VERSION "STEPFOC V108"

NS_ :

BS_:

BU_: Host Driver0 Driver1 Driver2 Driver3 Driver4 Driver5 Driver6 Driver7 Driver8 Driver9 Driver10 Driver11 Driver12 Driver13

BO_ 958 Send_data_pack_HALL_N7: 4 Host
 SG_ Speed : 7|24@0- (1,0) [-8388608|8388607] "" Driver7
 SG_ Trigger : 31|8@0+ (1,0) [0|255] "" Driver7

BO_ 902 Respond_data_pack_1_N7: 8 Driver7
 SG_ position : 7|24@0- (1,0) [-8388608|8388607] "" Host
 SG_ speed : 31|24@0- (1,0) [-8388608|8388607] "" Host
 SG_ current : 55|16@0- (1,0) [-32768|32767] "" Host

BO_ 903 Respond_data_pack_1_N7_Fault: 8 Driver7
 SG_ position : 7|24@0- (1,0) [-8388608|8388607] "" Host
 SG_ speed : 31|24@0- (1,0) [-8388608|8388607] "" Host
 SG_ current : 55|16@0- (1,0) [-32768|32767] "" Host

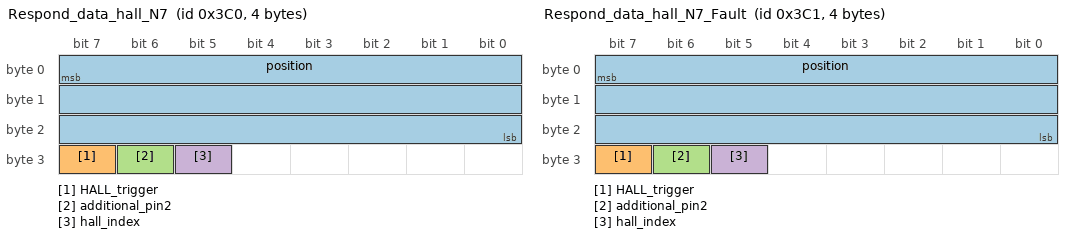
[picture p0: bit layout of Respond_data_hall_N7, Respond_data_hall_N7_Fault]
BO_ 960 Respond_data_hall_N7: 4 Driver7
 SG_ position : 7|24@0- (1,0) [-8388608|8388607] "" Host
 SG_ HALL_trigger : 31|1@0+ (1,0) [0|1] "" Host
 SG_ additional_pin2 : 30|1@0+ (1,0) [0|1] "" Host
 SG_ hall_index : 29|1@0+ (1,0) [0|1] "" Host

BO_ 961 Respond_data_hall_N7_Fault: 4 Driver7
 SG_ position : 7|24@0- (1,0) [-8388608|8388607] "" Host
 SG_ HALL_trigger : 31|1@0+ (1,0) [0|1] "" Host
 SG_ additional_pin2 : 30|1@0+ (1,0) [0|1] "" Host
 SG_ hall_index : 29|1@0+ (1,0) [0|1] "" Host

BO_ 928 Send_PD_Gains_N7: 8 Host
 SG_ KP : 7|32@0+ (1,0) [-3.402823466e+38|3.402823466e+38] "" Driver7
 SG_ KD : 39|32@0+ (1,0) [-3.402823466e+38|3.402823466e+38] "" Driver7

BO_ 930 Send_Current_Gains_N7: 8 Host
 SG_ Kp_iq : 7|32@0+ (1,0) [-3.402823466e+38|3.402823466e+38] "" Driver7
 SG_ Ki_iq : 39|32@0+ (1,0) [-3.402823466e+38|3.402823466e+38] "" Driver7

BO_ 932 Send_Velocity_Gains_N7: 8 Host
 SG_ Kpv : 7|32@0+ (1,0) [-3.402823466e+38|3.402823466e+38] "" Driver7
 SG_ Kiv : 39|32@0+ (1,0) [-3.402823466e+38|3.402823466e+38] "" Driver7

BO_ 934 Send_Position_Gains_N7: 4 Host
 SG_ Kpp : 7|32@0+ (1,0) [-3.402823466e+38|3.402823466e+38] "" Driver7

BO_ 936 Send_Limits_N7: 8 Host
 SG_ Speed_limit : 7|32@0+ (1,0) [-3.402823466e+38|3.402823466e+38] "" Driver7
 SG_ Current_limit : 39|32@0+ (1,0) [-3.402823466e+38|3.402823466e+38] "" Driver7

BO_ 940 Send_Kt_N7: 4 Host
 SG_ Kt : 7|32@0+ (1,0) [-3.402823466e+38|3.402823466e+38] "" Driver7

BO_ 964 Send_Voltage_Limit_N7: 4 Host
 SG_ Voltage_limit : 7|32@0- (1,0) [-2147483648|2147483647] "" Driver7

BO_ 916 Send_Respond_Ping_N7: 0 Driver7

BO_ 917 Send_Respond_Ping_N7_Fault: 0 Driver7

BO_ 942 Send_Respond_Temperature_N7: 2 Driver7
 SG_ temperature : 7|16@0- (1,0) [-32768|32767] "" Host

BO_ 943 Send_Respond_Temperatur_N7_Fault: 2 Driver7
 SG_ temperature : 7|16@0- (1,0) [-32768|32767] "" Host

BO_ 944 Send_Respond_Voltage_N7: 2 Driver7
 SG_ voltage : 7|16@0+ (1,0) [0|65535] "" Host

BO_ 945 Send_Respond_Voltage_N7_Fault: 2 Driver7
 SG_ voltage : 7|16@0+ (1,0) [0|65535] "" Host

BO_ 946 Send_Respond_Device_Info_N7: 7 Driver7
 SG_ HARDWARE_VERSION : 7|8@0+ (1,0) [0|255] "" Host
 SG_ BATCH_DATE : 15|8@0+ (1,0) [0|255] "" Host
 SG_ SOFTWARE_VERSION : 23|8@0+ (1,0) [0|255] "" Host
 SG_ SERIAL_NUMBER : 31|32@0+ (1,0) [0|4294967295] "" Host

BO_ 947 Send_Respond_Device_Inf_N7_Fault: 7 Driver7
 SG_ HARDWARE_VERSION : 7|8@0+ (1,0) [0|255] "" Host
 SG_ BATCH_DATE : 15|8@0+ (1,0) [0|255] "" Host
 SG_ SOFTWARE_VERSION : 23|8@0+ (1,0) [0|255] "" Host
 SG_ SERIAL_NUMBER : 31|32@0+ (1,0) [0|4294967295] "" Host

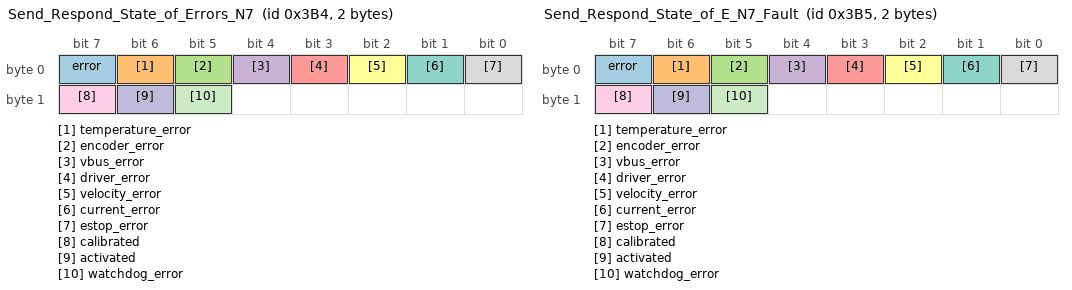
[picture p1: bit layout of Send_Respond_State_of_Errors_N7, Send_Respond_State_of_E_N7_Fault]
BO_ 948 Send_Respond_State_of_Errors_N7: 2 Driver7
 SG_ error : 7|1@0+ (1,0) [0|1] "" Host
 SG_ temperature_error : 6|1@0+ (1,0) [0|1] "" Host
 SG_ encoder_error : 5|1@0+ (1,0) [0|1] "" Host
 SG_ vbus_error : 4|1@0+ (1,0) [0|1] "" Host
 SG_ driver_error : 3|1@0+ (1,0) [0|1] "" Host
 SG_ velocity_error : 2|1@0+ (1,0) [0|1] "" Host
 SG_ current_error : 1|1@0+ (1,0) [0|1] "" Host
 SG_ estop_error : 0|1@0+ (1,0) [0|1] "" Host
 SG_ calibrated : 15|1@0+ (1,0) [0|1] "" Host
 SG_ activated : 14|1@0+ (1,0) [0|1] "" Host
 SG_ watchdog_error : 13|1@0+ (1,0) [0|1] "" Host

BO_ 949 Send_Respond_State_of_E_N7_Fault: 2 Driver7
 SG_ error : 7|1@0+ (1,0) [0|1] "" Host
 SG_ temperature_error : 6|1@0+ (1,0) [0|1] "" Host
 SG_ encoder_error : 5|1@0+ (1,0) [0|1] "" Host
 SG_ vbus_error : 4|1@0+ (1,0) [0|1] "" Host
 SG_ driver_error : 3|1@0+ (1,0) [0|1] "" Host
 SG_ velocity_error : 2|1@0+ (1,0) [0|1] "" Host
 SG_ current_error : 1|1@0+ (1,0) [0|1] "" Host
 SG_ estop_error : 0|1@0+ (1,0) [0|1] "" Host
 SG_ calibrated : 15|1@0+ (1,0) [0|1] "" Host
 SG_ activated : 14|1@0+ (1,0) [0|1] "" Host
 SG_ watchdog_error : 13|1@0+ (1,0) [0|1] "" Host

BO_ 950 Send_Respond_Iq_data_N7: 2 Driver7
 SG_ current : 7|16@0- (1,0) [-32768|32767] "" Host

BO_ 951 Send_Respond_Iq_data_N7_Fault: 2 Driver7
 SG_ current : 7|16@0- (1,0) [-32768|32767] "" Host

BO_ 952 Send_Respond_Encoder_data_N7: 8 Driver7
 SG_ position : 7|32@0- (1,0) [-2147483648|2147483647] "" Host
 SG_ speed : 39|32@0- (1,0) [-2147483648|2147483647] "" Host

BO_ 953 Send_Respond_Encoder_da_N7_Fault: 8 Driver7
 SG_ position : 7|32@0- (1,0) [-2147483648|2147483647] "" Host
 SG_ speed : 39|32@0- (1,0) [-2147483648|2147483647] "" Host

BO_ 962 Send_Respond_Kt_N7: 4 Driver7
 SG_ Kt : 7|32@0+ (1,0) [-3.402823466e+38|3.402823466e+38] "" Host

BO_ 963 Send_Respond_Kt_N7_Fault: 4 Driver7
 SG_ Kt : 7|32@0+ (1,0) [-3.402823466e+38|3.402823466e+38] "" Host

BO_ 914 Respond_Heartbeat_N7: 0 Driver7

BO_ 915 Respond_Heartbeat_N7_Fault: 0 Driver7

BO_ 918 Send_CAN_ID_N7: 1 Host
 SG_ ID : 7|8@0+ (1,0) [0|255] "" Driver7

BO_ 896 Send_ESTOP_N7: 0 Host

BO_ 920 Send_Idle_N7: 0 Host

BO_ 922 Send_Save_config_N7: 0 Host

BO_ 924 Send_Reset_N7: 0 Host

BO_ 898 Send_Clear_Error_N7: 0 Host

BO_ 926 Send_Watchdog_N7: 5 Host
 SG_ Time : 7|32@0+ (1,0) [0|4294967295] "" Driver7
 SG_ Action : 39|8@0+ (1,0) [0|255] "" Driver7

BO_ 956 Send_Heartbeat_Setup_N7: 4 Host
 SG_ Interval : 7|32@0+ (1,0) [0|4294967295] "" Driver7

BO_ 966 Send_Settings_N7: 2 Host
 SG_ Mask : 7|8@0+ (1,0) [0|255] "" Driver7
 SG_ Value : 15|8@0+ (1,0) [0|255] "" Driver7

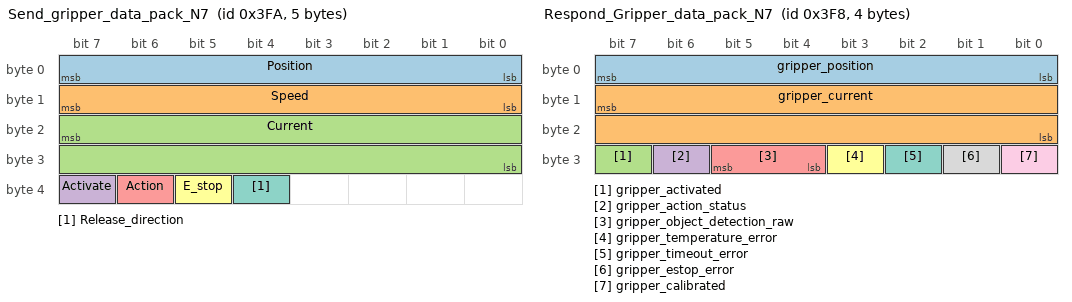
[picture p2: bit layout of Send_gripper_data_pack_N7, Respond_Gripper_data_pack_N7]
BO_ 1018 Send_gripper_data_pack_N7: 5 Host
 SG_ Position : 7|8@0+ (1,0) [0|255] "" Driver7
 SG_ Speed : 15|8@0+ (1,0) [0|255] "" Driver7
 SG_ Current : 23|16@0- (1,0) [-32768|32767] "" Driver7
 SG_ Activate : 39|1@0+ (1,0) [0|1] "" Driver7
 SG_ Action : 38|1@0+ (1,0) [0|1] "" Driver7
 SG_ E_stop : 37|1@0+ (1,0) [0|1] "" Driver7
 SG_ Release_direction : 36|1@0+ (1,0) [0|1] "" Driver7

BO_ 1020 Send_gripper_calibrate_N7: 0 Host

BO_ 1016 Respond_Gripper_data_pack_N7: 4 Driver7
 SG_ gripper_position : 7|8@0+ (1,0) [0|255] "" Host
 SG_ gripper_current : 15|16@0- (1,0) [-32768|32767] "" Host
 SG_ gripper_activated : 31|1@0+ (1,0) [0|1] "" Host
 SG_ gripper_action_status : 30|1@0+ (1,0) [0|1] "" Host
 SG_ gripper_object_detection_raw : 29|2@0+ (1,0) [0|3] "" Host
 SG_ gripper_temperature_error : 27|1@0+ (1,0) [0|1] "" Host
 SG_ gripper_timeout_error : 26|1@0+ (1,0) [0|1] "" Host
 SG_ gripper_estop_error : 25|1@0+ (1,0) [0|1] "" Host
 SG_ gripper_calibrated : 24|1@0+ (1,0) [0|1] "" Host

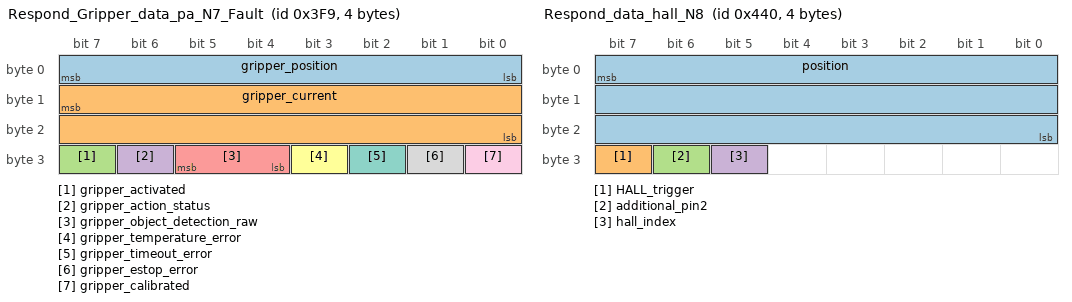
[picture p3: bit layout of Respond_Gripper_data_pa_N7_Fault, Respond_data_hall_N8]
BO_ 1017 Respond_Gripper_data_pa_N7_Fault: 4 Driver7
 SG_ gripper_position : 7|8@0+ (1,0) [0|255] "" Host
 SG_ gripper_current : 15|16@0- (1,0) [-32768|32767] "" Host
 SG_ gripper_activated : 31|1@0+ (1,0) [0|1] "" Host
 SG_ gripper_action_status : 30|1@0+ (1,0) [0|1] "" Host
 SG_ gripper_object_detection_raw : 29|2@0+ (1,0) [0|3] "" Host
 SG_ gripper_temperature_error : 27|1@0+ (1,0) [0|1] "" Host
 SG_ gripper_timeout_error : 26|1@0+ (1,0) [0|1] "" Host
 SG_ gripper_estop_error : 25|1@0+ (1,0) [0|1] "" Host
 SG_ gripper_calibrated : 24|1@0+ (1,0) [0|1] "" Host

BO_ 1028 Send_data_pack_1_N8: 5 Host
 SG_ Speed_setpoint : 7|24@0- (1,0) [-8388608|8388607] "" Driver8
 SG_ Current_feedforward : 31|16@0- (1,0) [-32768|32767] "" Driver8

BO_ 1032 Send_data_pack_PD_N8: 8 Host
 SG_ Position_setpoint : 7|24@0- (1,0) [-8388608|8388607] "" Driver8
 SG_ Speed_setpoint : 31|24@0- (1,0) [-8388608|8388607] "" Driver8
 SG_ Current_feedforward : 55|16@0- (1,0) [-32768|32767] "" Driver8

BO_ 1086 Send_data_pack_HALL_N8: 4 Host
 SG_ Speed : 7|24@0- (1,0) [-8388608|8388607] "" Driver8
 SG_ Trigger : 31|8@0+ (1,0) [0|255] "" Driver8

BO_ 1030 Respond_data_pack_1_N8: 8 Driver8
 SG_ position : 7|24@0- (1,0) [-8388608|8388607] "" Host
 SG_ speed : 31|24@0- (1,0) [-8388608|8388607] "" Host
 SG_ current : 55|16@0- (1,0) [-32768|32767] "" Host

BO_ 1031 Respond_data_pack_1_N8_Fault: 8 Driver8
 SG_ position : 7|24@0- (1,0) [-8388608|8388607] "" Host
 SG_ speed : 31|24@0- (1,0) [-8388608|8388607] "" Host
 SG_ current : 55|16@0- (1,0) [-32768|32767] "" Host

BO_ 1088 Respond_data_hall_N8: 4 Driver8
 SG_ position : 7|24@0- (1,0) [-8388608|8388607] "" Host
 SG_ HALL_trigger : 31|1@0+ (1,0) [0|1] "" Host
 SG_ additional_pin2 : 30|1@0+ (1,0) [0|1] "" Host
 SG_ hall_index : 29|1@0+ (1,0) [0|1] "" Host

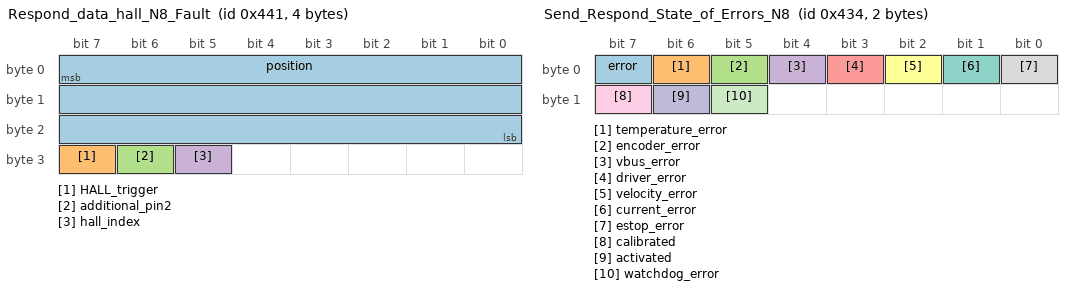
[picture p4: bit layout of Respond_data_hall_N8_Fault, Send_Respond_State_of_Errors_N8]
BO_ 1089 Respond_data_hall_N8_Fault: 4 Driver8
 SG_ position : 7|24@0- (1,0) [-8388608|8388607] "" Host
 SG_ HALL_trigger : 31|1@0+ (1,0) [0|1] "" Host
 SG_ additional_pin2 : 30|1@0+ (1,0) [0|1] "" Host
 SG_ hall_index : 29|1@0+ (1,0) [0|1] "" Host

BO_ 1056 Send_PD_Gains_N8: 8 Host
 SG_ KP : 7|32@0+ (1,0) [-3.402823466e+38|3.402823466e+38] "" Driver8
 SG_ KD : 39|32@0+ (1,0) [-3.402823466e+38|3.402823466e+38] "" Driver8

BO_ 1058 Send_Current_Gains_N8: 8 Host
 SG_ Kp_iq : 7|32@0+ (1,0) [-3.402823466e+38|3.402823466e+38] "" Driver8
 SG_ Ki_iq : 39|32@0+ (1,0) [-3.402823466e+38|3.402823466e+38] "" Driver8

BO_ 1060 Send_Velocity_Gains_N8: 8 Host
 SG_ Kpv : 7|32@0+ (1,0) [-3.402823466e+38|3.402823466e+38] "" Driver8
 SG_ Kiv : 39|32@0+ (1,0) [-3.402823466e+38|3.402823466e+38] "" Driver8

BO_ 1062 Send_Position_Gains_N8: 4 Host
 SG_ Kpp : 7|32@0+ (1,0) [-3.402823466e+38|3.402823466e+38] "" Driver8

BO_ 1064 Send_Limits_N8: 8 Host
 SG_ Speed_limit : 7|32@0+ (1,0) [-3.402823466e+38|3.402823466e+38] "" Driver8
 SG_ Current_limit : 39|32@0+ (1,0) [-3.402823466e+38|3.402823466e+38] "" Driver8

BO_ 1068 Send_Kt_N8: 4 Host
 SG_ Kt : 7|32@0+ (1,0) [-3.402823466e+38|3.402823466e+38] "" Driver8

BO_ 1092 Send_Voltage_Limit_N8: 4 Host
 SG_ Voltage_limit : 7|32@0- (1,0) [-2147483648|2147483647] "" Driver8

BO_ 1044 Send_Respond_Ping_N8: 0 Driver8

BO_ 1045 Send_Respond_Ping_N8_Fault: 0 Driver8

BO_ 1070 Send_Respond_Temperature_N8: 2 Driver8
 SG_ temperature : 7|16@0- (1,0) [-32768|32767] "" Host

BO_ 1071 Send_Respond_Temperatur_N8_Fault: 2 Driver8
 SG_ temperature : 7|16@0- (1,0) [-32768|32767] "" Host

BO_ 1072 Send_Respond_Voltage_N8: 2 Driver8
 SG_ voltage : 7|16@0+ (1,0) [0|65535] "" Host

BO_ 1073 Send_Respond_Voltage_N8_Fault: 2 Driver8
 SG_ voltage : 7|16@0+ (1,0) [0|65535] "" Host

BO_ 1074 Send_Respond_Device_Info_N8: 7 Driver8
 SG_ HARDWARE_VERSION : 7|8@0+ (1,0) [0|255] "" Host
 SG_ BATCH_DATE : 15|8@0+ (1,0) [0|255] "" Host
 SG_ SOFTWARE_VERSION : 23|8@0+ (1,0) [0|255] "" Host
 SG_ SERIAL_NUMBER : 31|32@0+ (1,0) [0|4294967295] "" Host

BO_ 1075 Send_Respond_Device_Inf_N8_Fault: 7 Driver8
 SG_ HARDWARE_VERSION : 7|8@0+ (1,0) [0|255] "" Host
 SG_ BATCH_DATE : 15|8@0+ (1,0) [0|255] "" Host
 SG_ SOFTWARE_VERSION : 23|8@0+ (1,0) [0|255] "" Host
 SG_ SERIAL_NUMBER : 31|32@0+ (1,0) [0|4294967295] "" Host

BO_ 1076 Send_Respond_State_of_Errors_N8: 2 Driver8
 SG_ error : 7|1@0+ (1,0) [0|1] "" Host
 SG_ temperature_error : 6|1@0+ (1,0) [0|1] "" Host
 SG_ encoder_error : 5|1@0+ (1,0) [0|1] "" Host
 SG_ vbus_error : 4|1@0+ (1,0) [0|1] "" Host
 SG_ driver_error : 3|1@0+ (1,0) [0|1] "" Host
 SG_ velocity_error : 2|1@0+ (1,0) [0|1] "" Host
 SG_ current_error : 1|1@0+ (1,0) [0|1] "" Host
 SG_ estop_error : 0|1@0+ (1,0) [0|1] "" Host
 SG_ calibrated : 15|1@0+ (1,0) [0|1] "" Host
 SG_ activated : 14|1@0+ (1,0) [0|1] "" Host
 SG_ watchdog_error : 13|1@0+ (1,0) [0|1] "" Host

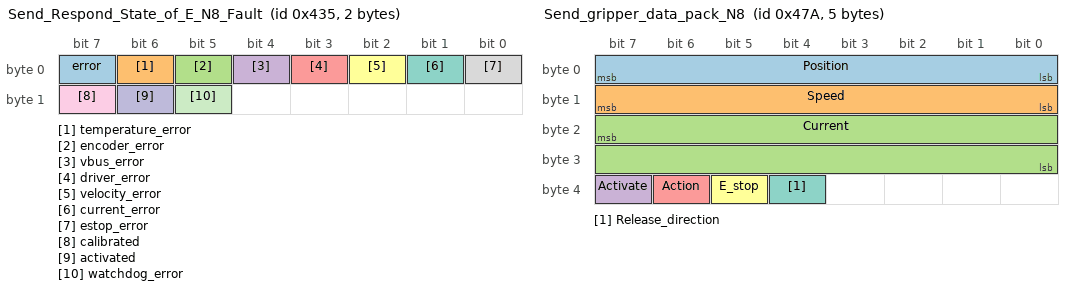
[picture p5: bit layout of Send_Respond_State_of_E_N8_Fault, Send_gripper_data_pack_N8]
BO_ 1077 Send_Respond_State_of_E_N8_Fault: 2 Driver8
 SG_ error : 7|1@0+ (1,0) [0|1] "" Host
 SG_ temperature_error : 6|1@0+ (1,0) [0|1] "" Host
 SG_ encoder_error : 5|1@0+ (1,0) [0|1] "" Host
 SG_ vbus_error : 4|1@0+ (1,0) [0|1] "" Host
 SG_ driver_error : 3|1@0+ (1,0) [0|1] "" Host
 SG_ velocity_error : 2|1@0+ (1,0) [0|1] "" Host
 SG_ current_error : 1|1@0+ (1,0) [0|1] "" Host
 SG_ estop_error : 0|1@0+ (1,0) [0|1] "" Host
 SG_ calibrated : 15|1@0+ (1,0) [0|1] "" Host
 SG_ activated : 14|1@0+ (1,0) [0|1] "" Host
 SG_ watchdog_error : 13|1@0+ (1,0) [0|1] "" Host

BO_ 1078 Send_Respond_Iq_data_N8: 2 Driver8
 SG_ current : 7|16@0- (1,0) [-32768|32767] "" Host

BO_ 1079 Send_Respond_Iq_data_N8_Fault: 2 Driver8
 SG_ current : 7|16@0- (1,0) [-32768|32767] "" Host

BO_ 1080 Send_Respond_Encoder_data_N8: 8 Driver8
 SG_ position : 7|32@0- (1,0) [-2147483648|2147483647] "" Host
 SG_ speed : 39|32@0- (1,0) [-2147483648|2147483647] "" Host

BO_ 1081 Send_Respond_Encoder_da_N8_Fault: 8 Driver8
 SG_ position : 7|32@0- (1,0) [-2147483648|2147483647] "" Host
 SG_ speed : 39|32@0- (1,0) [-2147483648|2147483647] "" Host

BO_ 1090 Send_Respond_Kt_N8: 4 Driver8
 SG_ Kt : 7|32@0+ (1,0) [-3.402823466e+38|3.402823466e+38] "" Host

BO_ 1091 Send_Respond_Kt_N8_Fault: 4 Driver8
 SG_ Kt : 7|32@0+ (1,0) [-3.402823466e+38|3.402823466e+38] "" Host

BO_ 1042 Respond_Heartbeat_N8: 0 Driver8

BO_ 1043 Respond_Heartbeat_N8_Fault: 0 Driver8

BO_ 1046 Send_CAN_ID_N8: 1 Host
 SG_ ID : 7|8@0+ (1,0) [0|255] "" Driver8

BO_ 1024 Send_ESTOP_N8: 0 Host

BO_ 1048 Send_Idle_N8: 0 Host

BO_ 1050 Send_Save_config_N8: 0 Host

BO_ 1052 Send_Reset_N8: 0 Host

BO_ 1026 Send_Clear_Error_N8: 0 Host

BO_ 1054 Send_Watchdog_N8: 5 Host
 SG_ Time : 7|32@0+ (1,0) [0|4294967295] "" Driver8
 SG_ Action : 39|8@0+ (1,0) [0|255] "" Driver8

BO_ 1084 Send_Heartbeat_Setup_N8: 4 Host
 SG_ Interval : 7|32@0+ (1,0) [0|4294967295] "" Driver8

BO_ 1094 Send_Settings_N8: 2 Host
 SG_ Mask : 7|8@0+ (1,0) [0|255] "" Driver8
 SG_ Value : 15|8@0+ (1,0) [0|255] "" Driver8

BO_ 1146 Send_gripper_data_pack_N8: 5 Host
 SG_ Position : 7|8@0+ (1,0) [0|255] "" Driver8
 SG_ Speed : 15|8@0+ (1,0) [0|255] "" Driver8
 SG_ Current : 23|16@0- (1,0) [-32768|32767] "" Driver8
 SG_ Activate : 39|1@0+ (1,0) [0|1] "" Driver8
 SG_ Action : 38|1@0+ (1,0) [0|1] "" Driver8
 SG_ E_stop : 37|1@0+ (1,0) [0|1] "" Driver8
 SG_ Release_direction : 36|1@0+ (1,0) [0|1] "" Driver8

BO_ 1148 Send_gripper_calibrate_N8: 0 Host

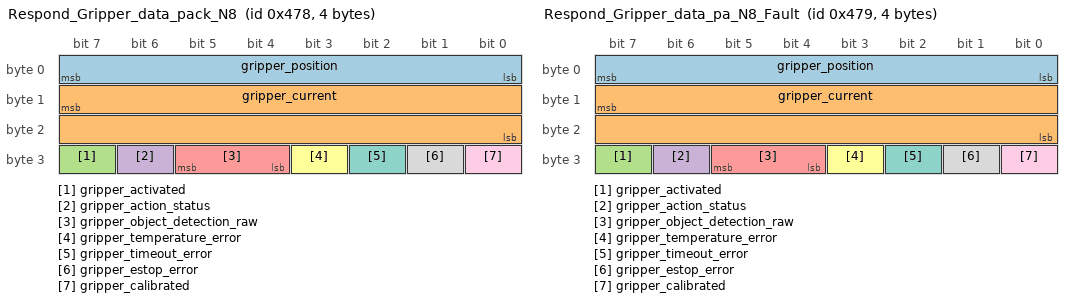
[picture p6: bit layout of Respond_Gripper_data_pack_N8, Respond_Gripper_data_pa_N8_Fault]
BO_ 1144 Respond_Gripper_data_pack_N8: 4 Driver8
 SG_ gripper_position : 7|8@0+ (1,0) [0|255] "" Host
 SG_ gripper_current : 15|16@0- (1,0) [-32768|32767] "" Host
 SG_ gripper_activated : 31|1@0+ (1,0) [0|1] "" Host
 SG_ gripper_action_status : 30|1@0+ (1,0) [0|1] "" Host
 SG_ gripper_object_detection_raw : 29|2@0+ (1,0) [0|3] "" Host
 SG_ gripper_temperature_error : 27|1@0+ (1,0) [0|1] "" Host
 SG_ gripper_timeout_error : 26|1@0+ (1,0) [0|1] "" Host
 SG_ gripper_estop_error : 25|1@0+ (1,0) [0|1] "" Host
 SG_ gripper_calibrated : 24|1@0+ (1,0) [0|1] "" Host

BO_ 1145 Respond_Gripper_data_pa_N8_Fault: 4 Driver8
 SG_ gripper_position : 7|8@0+ (1,0) [0|255] "" Host
 SG_ gripper_current : 15|16@0- (1,0) [-32768|32767] "" Host
 SG_ gripper_activated : 31|1@0+ (1,0) [0|1] "" Host
 SG_ gripper_action_status : 30|1@0+ (1,0) [0|1] "" Host
 SG_ gripper_object_detection_raw : 29|2@0+ (1,0) [0|3] "" Host
 SG_ gripper_temperature_error : 27|1@0+ (1,0) [0|1] "" Host
 SG_ gripper_timeout_error : 26|1@0+ (1,0) [0|1] "" Host
 SG_ gripper_estop_error : 25|1@0+ (1,0) [0|1] "" Host
 SG_ gripper_calibrated : 24|1@0+ (1,0) [0|1] "" Host

BO_ 1156 Send_data_pack_1_N9: 5 Host
 SG_ Speed_setpoint : 7|24@0- (1,0) [-8388608|8388607] "" Driver9
 SG_ Current_feedforward : 31|16@0- (1,0) [-32768|32767] "" Driver9

BO_ 1160 Send_data_pack_PD_N9: 8 Host
 SG_ Position_setpoint : 7|24@0- (1,0) [-8388608|8388607] "" Driver9
 SG_ Speed_setpoint : 31|24@0- (1,0) [-8388608|8388607] "" Driver9
 SG_ Current_feedforward : 55|16@0- (1,0) [-32768|32767] "" Driver9

BO_ 1214 Send_data_pack_HALL_N9: 4 Host
 SG_ Speed : 7|24@0- (1,0) [-8388608|8388607] "" Driver9
 SG_ Trigger : 31|8@0+ (1,0) [0|255] "" Driver9

BO_ 1158 Respond_data_pack_1_N9: 8 Driver9
 SG_ position : 7|24@0- (1,0) [-8388608|8388607] "" Host
 SG_ speed : 31|24@0- (1,0) [-8388608|8388607] "" Host
 SG_ current : 55|16@0- (1,0) [-32768|32767] "" Host

BO_ 1159 Respond_data_pack_1_N9_Fault: 8 Driver9
 SG_ position : 7|24@0- (1,0) [-8388608|8388607] "" Host
 SG_ speed : 31|24@0- (1,0) [-8388608|8388607] "" Host
 SG_ current : 55|16@0- (1,0) [-32768|32767] "" Host

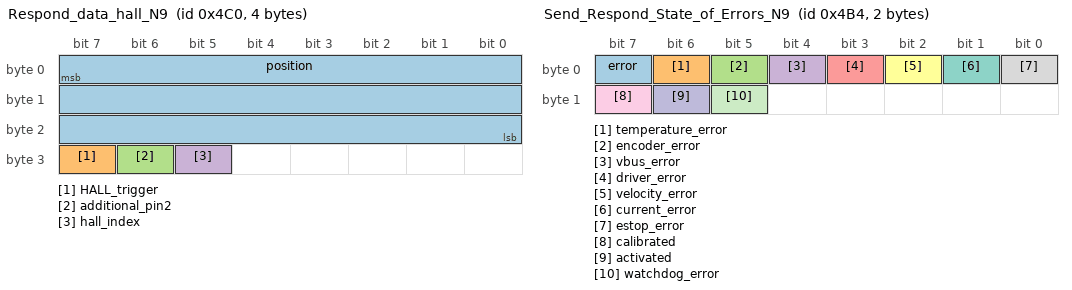
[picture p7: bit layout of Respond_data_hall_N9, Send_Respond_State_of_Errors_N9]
BO_ 1216 Respond_data_hall_N9: 4 Driver9
 SG_ position : 7|24@0- (1,0) [-8388608|8388607] "" Host
 SG_ HALL_trigger : 31|1@0+ (1,0) [0|1] "" Host
 SG_ additional_pin2 : 30|1@0+ (1,0) [0|1] "" Host
 SG_ hall_index : 29|1@0+ (1,0) [0|1] "" Host

BO_ 1217 Respond_data_hall_N9_Fault: 4 Driver9
 SG_ position : 7|24@0- (1,0) [-8388608|8388607] "" Host
 SG_ HALL_trigger : 31|1@0+ (1,0) [0|1] "" Host
 SG_ additional_pin2 : 30|1@0+ (1,0) [0|1] "" Host
 SG_ hall_index : 29|1@0+ (1,0) [0|1] "" Host

BO_ 1184 Send_PD_Gains_N9: 8 Host
 SG_ KP : 7|32@0+ (1,0) [-3.402823466e+38|3.402823466e+38] "" Driver9
 SG_ KD : 39|32@0+ (1,0) [-3.402823466e+38|3.402823466e+38] "" Driver9

BO_ 1186 Send_Current_Gains_N9: 8 Host
 SG_ Kp_iq : 7|32@0+ (1,0) [-3.402823466e+38|3.402823466e+38] "" Driver9
 SG_ Ki_iq : 39|32@0+ (1,0) [-3.402823466e+38|3.402823466e+38] "" Driver9

BO_ 1188 Send_Velocity_Gains_N9: 8 Host
 SG_ Kpv : 7|32@0+ (1,0) [-3.402823466e+38|3.402823466e+38] "" Driver9
 SG_ Kiv : 39|32@0+ (1,0) [-3.402823466e+38|3.402823466e+38] "" Driver9

BO_ 1190 Send_Position_Gains_N9: 4 Host
 SG_ Kpp : 7|32@0+ (1,0) [-3.402823466e+38|3.402823466e+38] "" Driver9

BO_ 1192 Send_Limits_N9: 8 Host
 SG_ Speed_limit : 7|32@0+ (1,0) [-3.402823466e+38|3.402823466e+38] "" Driver9
 SG_ Current_limit : 39|32@0+ (1,0) [-3.402823466e+38|3.402823466e+38] "" Driver9

BO_ 1196 Send_Kt_N9: 4 Host
 SG_ Kt : 7|32@0+ (1,0) [-3.402823466e+38|3.402823466e+38] "" Driver9

BO_ 1220 Send_Voltage_Limit_N9: 4 Host
 SG_ Voltage_limit : 7|32@0- (1,0) [-2147483648|2147483647] "" Driver9

BO_ 1172 Send_Respond_Ping_N9: 0 Driver9

BO_ 1173 Send_Respond_Ping_N9_Fault: 0 Driver9

BO_ 1198 Send_Respond_Temperature_N9: 2 Driver9
 SG_ temperature : 7|16@0- (1,0) [-32768|32767] "" Host

BO_ 1199 Send_Respond_Temperatur_N9_Fault: 2 Driver9
 SG_ temperature : 7|16@0- (1,0) [-32768|32767] "" Host

BO_ 1200 Send_Respond_Voltage_N9: 2 Driver9
 SG_ voltage : 7|16@0+ (1,0) [0|65535] "" Host

BO_ 1201 Send_Respond_Voltage_N9_Fault: 2 Driver9
 SG_ voltage : 7|16@0+ (1,0) [0|65535] "" Host

BO_ 1202 Send_Respond_Device_Info_N9: 7 Driver9
 SG_ HARDWARE_VERSION : 7|8@0+ (1,0) [0|255] "" Host
 SG_ BATCH_DATE : 15|8@0+ (1,0) [0|255] "" Host
 SG_ SOFTWARE_VERSION : 23|8@0+ (1,0) [0|255] "" Host
 SG_ SERIAL_NUMBER : 31|32@0+ (1,0) [0|4294967295] "" Host

BO_ 1203 Send_Respond_Device_Inf_N9_Fault: 7 Driver9
 SG_ HARDWARE_VERSION : 7|8@0+ (1,0) [0|255] "" Host
 SG_ BATCH_DATE : 15|8@0+ (1,0) [0|255] "" Host
 SG_ SOFTWARE_VERSION : 23|8@0+ (1,0) [0|255] "" Host
 SG_ SERIAL_NUMBER : 31|32@0+ (1,0) [0|4294967295] "" Host

BO_ 1204 Send_Respond_State_of_Errors_N9: 2 Driver9
 SG_ error : 7|1@0+ (1,0) [0|1] "" Host
 SG_ temperature_error : 6|1@0+ (1,0) [0|1] "" Host
 SG_ encoder_error : 5|1@0+ (1,0) [0|1] "" Host
 SG_ vbus_error : 4|1@0+ (1,0) [0|1] "" Host
 SG_ driver_error : 3|1@0+ (1,0) [0|1] "" Host
 SG_ velocity_error : 2|1@0+ (1,0) [0|1] "" Host
 SG_ current_error : 1|1@0+ (1,0) [0|1] "" Host
 SG_ estop_error : 0|1@0+ (1,0) [0|1] "" Host
 SG_ calibrated : 15|1@0+ (1,0) [0|1] "" Host
 SG_ activated : 14|1@0+ (1,0) [0|1] "" Host
 SG_ watchdog_error : 13|1@0+ (1,0) [0|1] "" Host

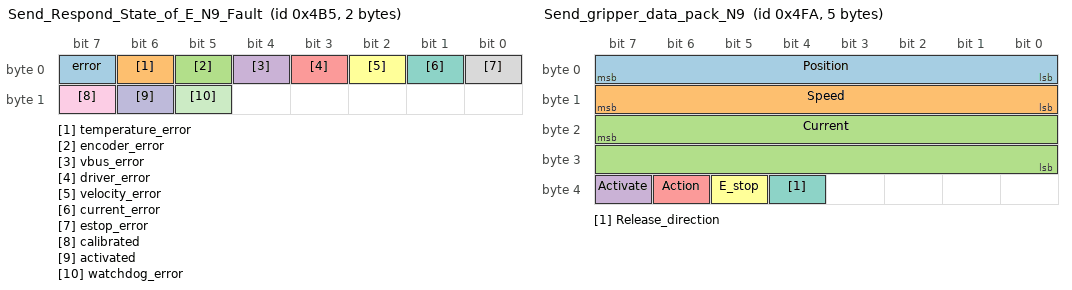
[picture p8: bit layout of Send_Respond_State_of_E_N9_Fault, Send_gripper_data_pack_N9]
BO_ 1205 Send_Respond_State_of_E_N9_Fault: 2 Driver9
 SG_ error : 7|1@0+ (1,0) [0|1] "" Host
 SG_ temperature_error : 6|1@0+ (1,0) [0|1] "" Host
 SG_ encoder_error : 5|1@0+ (1,0) [0|1] "" Host
 SG_ vbus_error : 4|1@0+ (1,0) [0|1] "" Host
 SG_ driver_error : 3|1@0+ (1,0) [0|1] "" Host
 SG_ velocity_error : 2|1@0+ (1,0) [0|1] "" Host
 SG_ current_error : 1|1@0+ (1,0) [0|1] "" Host
 SG_ estop_error : 0|1@0+ (1,0) [0|1] "" Host
 SG_ calibrated : 15|1@0+ (1,0) [0|1] "" Host
 SG_ activated : 14|1@0+ (1,0) [0|1] "" Host
 SG_ watchdog_error : 13|1@0+ (1,0) [0|1] "" Host

BO_ 1206 Send_Respond_Iq_data_N9: 2 Driver9
 SG_ current : 7|16@0- (1,0) [-32768|32767] "" Host

BO_ 1207 Send_Respond_Iq_data_N9_Fault: 2 Driver9
 SG_ current : 7|16@0- (1,0) [-32768|32767] "" Host

BO_ 1208 Send_Respond_Encoder_data_N9: 8 Driver9
 SG_ position : 7|32@0- (1,0) [-2147483648|2147483647] "" Host
 SG_ speed : 39|32@0- (1,0) [-2147483648|2147483647] "" Host

BO_ 1209 Send_Respond_Encoder_da_N9_Fault: 8 Driver9
 SG_ position : 7|32@0- (1,0) [-2147483648|2147483647] "" Host
 SG_ speed : 39|32@0- (1,0) [-2147483648|2147483647] "" Host

BO_ 1218 Send_Respond_Kt_N9: 4 Driver9
 SG_ Kt : 7|32@0+ (1,0) [-3.402823466e+38|3.402823466e+38] "" Host

BO_ 1219 Send_Respond_Kt_N9_Fault: 4 Driver9
 SG_ Kt : 7|32@0+ (1,0) [-3.402823466e+38|3.402823466e+38] "" Host

BO_ 1170 Respond_Heartbeat_N9: 0 Driver9

BO_ 1171 Respond_Heartbeat_N9_Fault: 0 Driver9

BO_ 1174 Send_CAN_ID_N9: 1 Host
 SG_ ID : 7|8@0+ (1,0) [0|255] "" Driver9

BO_ 1152 Send_ESTOP_N9: 0 Host

BO_ 1176 Send_Idle_N9: 0 Host

BO_ 1178 Send_Save_config_N9: 0 Host

BO_ 1180 Send_Reset_N9: 0 Host

BO_ 1154 Send_Clear_Error_N9: 0 Host

BO_ 1182 Send_Watchdog_N9: 5 Host
 SG_ Time : 7|32@0+ (1,0) [0|4294967295] "" Driver9
 SG_ Action : 39|8@0+ (1,0) [0|255] "" Driver9

BO_ 1212 Send_Heartbeat_Setup_N9: 4 Host
 SG_ Interval : 7|32@0+ (1,0) [0|4294967295] "" Driver9

BO_ 1222 Send_Settings_N9: 2 Host
 SG_ Mask : 7|8@0+ (1,0) [0|255] "" Driver9
 SG_ Value : 15|8@0+ (1,0) [0|255] "" Driver9

BO_ 1274 Send_gripper_data_pack_N9: 5 Host
 SG_ Position : 7|8@0+ (1,0) [0|255] "" Driver9
 SG_ Speed : 15|8@0+ (1,0) [0|255] "" Driver9
 SG_ Current : 23|16@0- (1,0) [-32768|32767] "" Driver9
 SG_ Activate : 39|1@0+ (1,0) [0|1] "" Driver9
 SG_ Action : 38|1@0+ (1,0) [0|1] "" Driver9
 SG_ E_stop : 37|1@0+ (1,0) [0|1] "" Driver9
 SG_ Release_direction : 36|1@0+ (1,0) [0|1] "" Driver9

BO_ 1276 Send_gripper_calibrate_N9: 0 Host

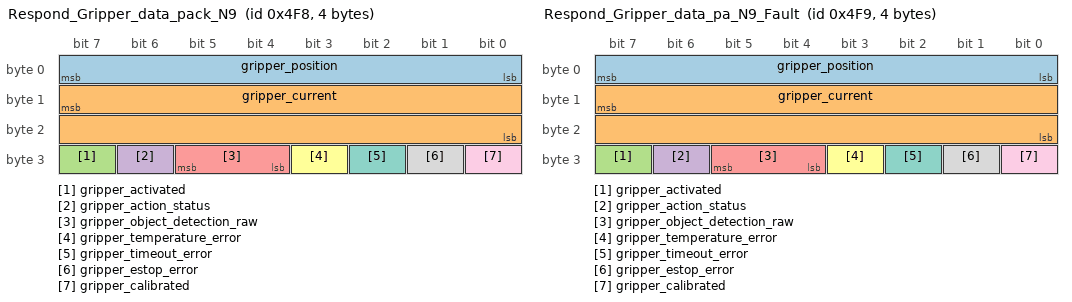
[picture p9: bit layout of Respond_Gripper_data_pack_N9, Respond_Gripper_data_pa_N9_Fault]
BO_ 1272 Respond_Gripper_data_pack_N9: 4 Driver9
 SG_ gripper_position : 7|8@0+ (1,0) [0|255] "" Host
 SG_ gripper_current : 15|16@0- (1,0) [-32768|32767] "" Host
 SG_ gripper_activated : 31|1@0+ (1,0) [0|1] "" Host
 SG_ gripper_action_status : 30|1@0+ (1,0) [0|1] "" Host
 SG_ gripper_object_detection_raw : 29|2@0+ (1,0) [0|3] "" Host
 SG_ gripper_temperature_error : 27|1@0+ (1,0) [0|1] "" Host
 SG_ gripper_timeout_error : 26|1@0+ (1,0) [0|1] "" Host
 SG_ gripper_estop_error : 25|1@0+ (1,0) [0|1] "" Host
 SG_ gripper_calibrated : 24|1@0+ (1,0) [0|1] "" Host

BO_ 1273 Respond_Gripper_data_pa_N9_Fault: 4 Driver9
 SG_ gripper_position : 7|8@0+ (1,0) [0|255] "" Host
 SG_ gripper_current : 15|16@0- (1,0) [-32768|32767] "" Host
 SG_ gripper_activated : 31|1@0+ (1,0) [0|1] "" Host
 SG_ gripper_action_status : 30|1@0+ (1,0) [0|1] "" Host
 SG_ gripper_object_detection_raw : 29|2@0+ (1,0) [0|3] "" Host
 SG_ gripper_temperature_error : 27|1@0+ (1,0) [0|1] "" Host
 SG_ gripper_timeout_error : 26|1@0+ (1,0) [0|1] "" Host
 SG_ gripper_estop_error : 25|1@0+ (1,0) [0|1] "" Host
 SG_ gripper_calibrated : 24|1@0+ (1,0) [0|1] "" Host

BO_ 1284 Send_data_pack_1_N10: 5 Host
 SG_ Speed_setpoint : 7|24@0- (1,0) [-8388608|8388607] "" Driver10
 SG_ Current_feedforward : 31|16@0- (1,0) [-32768|32767] "" Driver10

BO_ 1288 Send_data_pack_PD_N10: 8 Host
 SG_ Position_setpoint : 7|24@0- (1,0) [-8388608|8388607] "" Driver10
 SG_ Speed_setpoint : 31|24@0- (1,0) [-8388608|8388607] "" Driver10
 SG_ Current_feedforward : 55|16@0- (1,0) [-32768|32767] "" Driver10

BO_ 1342 Send_data_pack_HALL_N10: 4 Host
 SG_ Speed : 7|24@0- (1,0) [-8388608|8388607] "" Driver10
 SG_ Trigger : 31|8@0+ (1,0) [0|255] "" Driver10

BO_ 1286 Respond_data_pack_1_N10: 8 Driver10
 SG_ position : 7|24@0- (1,0) [-8388608|8388607] "" Host
 SG_ speed : 31|24@0- (1,0) [-8388608|8388607] "" Host
 SG_ current : 55|16@0- (1,0) [-32768|32767] "" Host

BO_ 1287 Respond_data_pack_1_N10_Fault: 8 Driver10
 SG_ position : 7|24@0- (1,0) [-8388608|8388607] "" Host
 SG_ speed : 31|24@0- (1,0) [-8388608|8388607] "" Host
 SG_ current : 55|16@0- (1,0) [-32768|32767] "" Host

BO_ 1344 Respond_data_hall_N10: 4 Driver10
 SG_ position : 7|24@0- (1,0) [-8388608|8388607] "" Host
 SG_ HALL_trigger : 31|1@0+ (1,0) [0|1] "" Host
 SG_ additional_pin2 : 30|1@0+ (1,0) [0|1] "" Host
 SG_ hall_index : 29|1@0+ (1,0) [0|1] "" Host

BO_ 1345 Respond_data_hall_N10_Fault: 4 Driver10
 SG_ position : 7|24@0- (1,0) [-8388608|8388607] "" Host
 SG_ HALL_trigger : 31|1@0+ (1,0) [0|1] "" Host
 SG_ additional_pin2 : 30|1@0+ (1,0) [0|1] "" Host
 SG_ hall_index : 29|1@0+ (1,0) [0|1] "" Host

BO_ 1312 Send_PD_Gains_N10: 8 Host
 SG_ KP : 7|32@0+ (1,0) [-3.402823466e+38|3.402823466e+38] "" Driver10
 SG_ KD : 39|32@0+ (1,0) [-3.402823466e+38|3.402823466e+38] "" Driver10

BO_ 1314 Send_Current_Gains_N10: 8 Host
 SG_ Kp_iq : 7|32@0+ (1,0) [-3.402823466e+38|3.402823466e+38] "" Driver10
 SG_ Ki_iq : 39|32@0+ (1,0) [-3.402823466e+38|3.402823466e+38] "" Driver10

BO_ 1316 Send_Velocity_Gains_N10: 8 Host
 SG_ Kpv : 7|32@0+ (1,0) [-3.402823466e+38|3.402823466e+38] "" Driver10
 SG_ Kiv : 39|32@0+ (1,0) [-3.402823466e+38|3.402823466e+38] "" Driver10

BO_ 1318 Send_Position_Gains_N10: 4 Host
 SG_ Kpp : 7|32@0+ (1,0) [-3.402823466e+38|3.402823466e+38] "" Driver10

BO_ 1320 Send_Limits_N10: 8 Host
 SG_ Speed_limit : 7|32@0+ (1,0) [-3.402823466e+38|3.402823466e+38] "" Driver10
 SG_ Current_limit : 39|32@0+ (1,0) [-3.402823466e+38|3.402823466e+38] "" Driver10

BO_ 1324 Send_Kt_N10: 4 Host
 SG_ Kt : 7|32@0+ (1,0) [-3.402823466e+38|3.402823466e+38] "" Driver10

BO_ 1348 Send_Voltage_Limit_N10: 4 Host
 SG_ Voltage_limit : 7|32@0- (1,0) [-2147483648|2147483647] "" Driver10

BO_ 1300 Send_Respond_Ping_N10: 0 Driver10

BO_ 1301 Send_Respond_Ping_N10_Fault: 0 Driver10

BO_ 1326 Send_Respond_Temperature_N10: 2 Driver10
 SG_ temperature : 7|16@0- (1,0) [-32768|32767] "" Host

BO_ 1327 Send_Respond_Temperatu_N10_Fault: 2 Driver10
 SG_ temperature : 7|16@0- (1,0) [-32768|32767] "" Host

BO_ 1328 Send_Respond_Voltage_N10: 2 Driver10
 SG_ voltage : 7|16@0+ (1,0) [0|65535] "" Host

BO_ 1329 Send_Respond_Voltage_N10_Fault: 2 Driver10
 SG_ voltage : 7|16@0+ (1,0) [0|65535] "" Host

BO_ 1330 Send_Respond_Device_Info_N10: 7 Driver10
 SG_ HARDWARE_VERSION : 7|8@0+ (1,0) [0|255] "" Host
 SG_ BATCH_DATE : 15|8@0+ (1,0) [0|255] "" Host
 SG_ SOFTWARE_VERSION : 23|8@0+ (1,0) [0|255] "" Host
 SG_ SERIAL_NUMBER : 31|32@0+ (1,0) [0|4294967295] "" Host

BO_ 1331 Send_Respond_Device_In_N10_Fault: 7 Driver10
 SG_ HARDWARE_VERSION : 7|8@0+ (1,0) [0|255] "" Host
 SG_ BATCH_DATE : 15|8@0+ (1,0) [0|255] "" Host
 SG_ SOFTWARE_VERSION : 23|8@0+ (1,0) [0|255] "" Host
 SG_ SERIAL_NUMBER : 31|32@0+ (1,0) [0|4294967295] "" Host

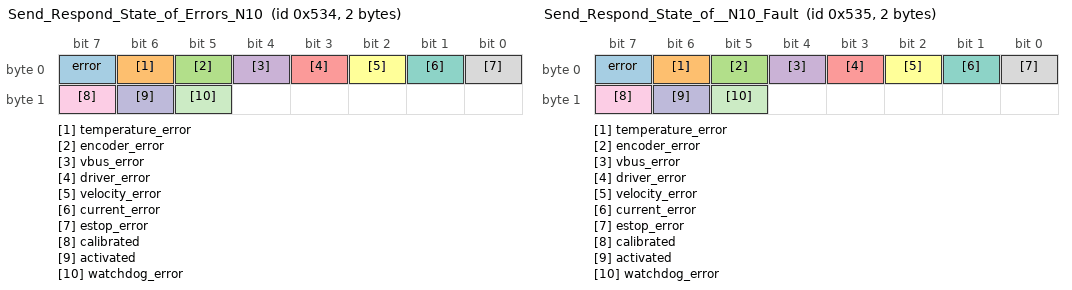
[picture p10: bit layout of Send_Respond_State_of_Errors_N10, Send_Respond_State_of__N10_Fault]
BO_ 1332 Send_Respond_State_of_Errors_N10: 2 Driver10
 SG_ error : 7|1@0+ (1,0) [0|1] "" Host
 SG_ temperature_error : 6|1@0+ (1,0) [0|1] "" Host
 SG_ encoder_error : 5|1@0+ (1,0) [0|1] "" Host
 SG_ vbus_error : 4|1@0+ (1,0) [0|1] "" Host
 SG_ driver_error : 3|1@0+ (1,0) [0|1] "" Host
 SG_ velocity_error : 2|1@0+ (1,0) [0|1] "" Host
 SG_ current_error : 1|1@0+ (1,0) [0|1] "" Host
 SG_ estop_error : 0|1@0+ (1,0) [0|1] "" Host
 SG_ calibrated : 15|1@0+ (1,0) [0|1] "" Host
 SG_ activated : 14|1@0+ (1,0) [0|1] "" Host
 SG_ watchdog_error : 13|1@0+ (1,0) [0|1] "" Host

BO_ 1333 Send_Respond_State_of__N10_Fault: 2 Driver10
 SG_ error : 7|1@0+ (1,0) [0|1] "" Host
 SG_ temperature_error : 6|1@0+ (1,0) [0|1] "" Host
 SG_ encoder_error : 5|1@0+ (1,0) [0|1] "" Host
 SG_ vbus_error : 4|1@0+ (1,0) [0|1] "" Host
 SG_ driver_error : 3|1@0+ (1,0) [0|1] "" Host
 SG_ velocity_error : 2|1@0+ (1,0) [0|1] "" Host
 SG_ current_error : 1|1@0+ (1,0) [0|1] "" Host
 SG_ estop_error : 0|1@0+ (1,0) [0|1] "" Host
 SG_ calibrated : 15|1@0+ (1,0) [0|1] "" Host
 SG_ activated : 14|1@0+ (1,0) [0|1] "" Host
 SG_ watchdog_error : 13|1@0+ (1,0) [0|1] "" Host

BO_ 1334 Send_Respond_Iq_data_N10: 2 Driver10
 SG_ current : 7|16@0- (1,0) [-32768|32767] "" Host

BO_ 1335 Send_Respond_Iq_data_N10_Fault: 2 Driver10
 SG_ current : 7|16@0- (1,0) [-32768|32767] "" Host

BO_ 1336 Send_Respond_Encoder_data_N10: 8 Driver10
 SG_ position : 7|32@0- (1,0) [-2147483648|2147483647] "" Host
 SG_ speed : 39|32@0- (1,0) [-2147483648|2147483647] "" Host

BO_ 1337 Send_Respond_Encoder_d_N10_Fault: 8 Driver10
 SG_ position : 7|32@0- (1,0) [-2147483648|2147483647] "" Host
 SG_ speed : 39|32@0- (1,0) [-2147483648|2147483647] "" Host

BO_ 1346 Send_Respond_Kt_N10: 4 Driver10
 SG_ Kt : 7|32@0+ (1,0) [-3.402823466e+38|3.402823466e+38] "" Host

BO_ 1347 Send_Respond_Kt_N10_Fault: 4 Driver10
 SG_ Kt : 7|32@0+ (1,0) [-3.402823466e+38|3.402823466e+38] "" Host

BO_ 1298 Respond_Heartbeat_N10: 0 Driver10

BO_ 1299 Respond_Heartbeat_N10_Fault: 0 Driver10

BO_ 1302 Send_CAN_ID_N10: 1 Host
 SG_ ID : 7|8@0+ (1,0) [0|255] "" Driver10

BO_ 1280 Send_ESTOP_N10: 0 Host

BO_ 1304 Send_Idle_N10: 0 Host

BO_ 1306 Send_Save_config_N10: 0 Host

BO_ 1308 Send_Reset_N10: 0 Host

BO_ 1282 Send_Clear_Error_N10: 0 Host

BO_ 1310 Send_Watchdog_N10: 5 Host
 SG_ Time : 7|32@0+ (1,0) [0|4294967295] "" Driver10
 SG_ Action : 39|8@0+ (1,0) [0|255] "" Driver10

BO_ 1340 Send_Heartbeat_Setup_N10: 4 Host
 SG_ Interval : 7|32@0+ (1,0) [0|4294967295] "" Driver10

BO_ 1350 Send_Settings_N10: 2 Host
 SG_ Mask : 7|8@0+ (1,0) [0|255] "" Driver10
 SG_ Value : 15|8@0+ (1,0) [0|255] "" Driver10

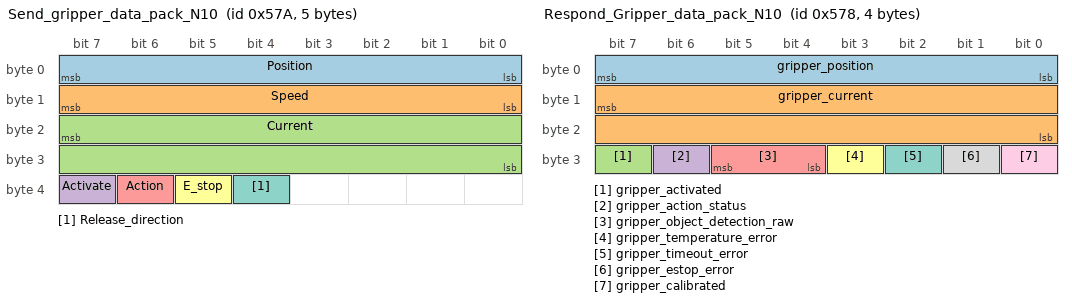
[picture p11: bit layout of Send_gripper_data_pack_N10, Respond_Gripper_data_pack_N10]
BO_ 1402 Send_gripper_data_pack_N10: 5 Host
 SG_ Position : 7|8@0+ (1,0) [0|255] "" Driver10
 SG_ Speed : 15|8@0+ (1,0) [0|255] "" Driver10
 SG_ Current : 23|16@0- (1,0) [-32768|32767] "" Driver10
 SG_ Activate : 39|1@0+ (1,0) [0|1] "" Driver10
 SG_ Action : 38|1@0+ (1,0) [0|1] "" Driver10
 SG_ E_stop : 37|1@0+ (1,0) [0|1] "" Driver10
 SG_ Release_direction : 36|1@0+ (1,0) [0|1] "" Driver10

BO_ 1404 Send_gripper_calibrate_N10: 0 Host

BO_ 1400 Respond_Gripper_data_pack_N10: 4 Driver10
 SG_ gripper_position : 7|8@0+ (1,0) [0|255] "" Host
 SG_ gripper_current : 15|16@0- (1,0) [-32768|32767] "" Host
 SG_ gripper_activated : 31|1@0+ (1,0) [0|1] "" Host
 SG_ gripper_action_status : 30|1@0+ (1,0) [0|1] "" Host
 SG_ gripper_object_detection_raw : 29|2@0+ (1,0) [0|3] "" Host
 SG_ gripper_temperature_error : 27|1@0+ (1,0) [0|1] "" Host
 SG_ gripper_timeout_error : 26|1@0+ (1,0) [0|1] "" Host
 SG_ gripper_estop_error : 25|1@0+ (1,0) [0|1] "" Host
 SG_ gripper_calibrated : 24|1@0+ (1,0) [0|1] "" Host

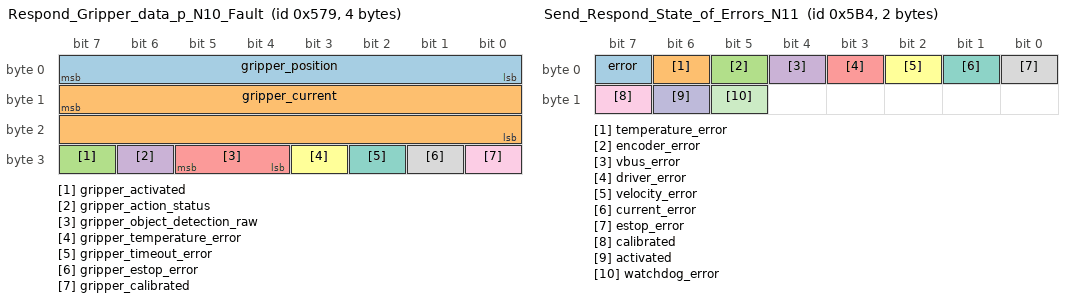
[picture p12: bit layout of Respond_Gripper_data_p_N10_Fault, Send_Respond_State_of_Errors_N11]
BO_ 1401 Respond_Gripper_data_p_N10_Fault: 4 Driver10
 SG_ gripper_position : 7|8@0+ (1,0) [0|255] "" Host
 SG_ gripper_current : 15|16@0- (1,0) [-32768|32767] "" Host
 SG_ gripper_activated : 31|1@0+ (1,0) [0|1] "" Host
 SG_ gripper_action_status : 30|1@0+ (1,0) [0|1] "" Host
 SG_ gripper_object_detection_raw : 29|2@0+ (1,0) [0|3] "" Host
 SG_ gripper_temperature_error : 27|1@0+ (1,0) [0|1] "" Host
 SG_ gripper_timeout_error : 26|1@0+ (1,0) [0|1] "" Host
 SG_ gripper_estop_error : 25|1@0+ (1,0) [0|1] "" Host
 SG_ gripper_calibrated : 24|1@0+ (1,0) [0|1] "" Host

BO_ 1412 Send_data_pack_1_N11: 5 Host
 SG_ Speed_setpoint : 7|24@0- (1,0) [-8388608|8388607] "" Driver11
 SG_ Current_feedforward : 31|16@0- (1,0) [-32768|32767] "" Driver11

BO_ 1416 Send_data_pack_PD_N11: 8 Host
 SG_ Position_setpoint : 7|24@0- (1,0) [-8388608|8388607] "" Driver11
 SG_ Speed_setpoint : 31|24@0- (1,0) [-8388608|8388607] "" Driver11
 SG_ Current_feedforward : 55|16@0- (1,0) [-32768|32767] "" Driver11

BO_ 1470 Send_data_pack_HALL_N11: 4 Host
 SG_ Speed : 7|24@0- (1,0) [-8388608|8388607] "" Driver11
 SG_ Trigger : 31|8@0+ (1,0) [0|255] "" Driver11

BO_ 1414 Respond_data_pack_1_N11: 8 Driver11
 SG_ position : 7|24@0- (1,0) [-8388608|8388607] "" Host
 SG_ speed : 31|24@0- (1,0) [-8388608|8388607] "" Host
 SG_ current : 55|16@0- (1,0) [-32768|32767] "" Host

BO_ 1415 Respond_data_pack_1_N11_Fault: 8 Driver11
 SG_ position : 7|24@0- (1,0) [-8388608|8388607] "" Host
 SG_ speed : 31|24@0- (1,0) [-8388608|8388607] "" Host
 SG_ current : 55|16@0- (1,0) [-32768|32767] "" Host

BO_ 1472 Respond_data_hall_N11: 4 Driver11
 SG_ position : 7|24@0- (1,0) [-8388608|8388607] "" Host
 SG_ HALL_trigger : 31|1@0+ (1,0) [0|1] "" Host
 SG_ additional_pin2 : 30|1@0+ (1,0) [0|1] "" Host
 SG_ hall_index : 29|1@0+ (1,0) [0|1] "" Host

BO_ 1473 Respond_data_hall_N11_Fault: 4 Driver11
 SG_ position : 7|24@0- (1,0) [-8388608|8388607] "" Host
 SG_ HALL_trigger : 31|1@0+ (1,0) [0|1] "" Host
 SG_ additional_pin2 : 30|1@0+ (1,0) [0|1] "" Host
 SG_ hall_index : 29|1@0+ (1,0) [0|1] "" Host

BO_ 1440 Send_PD_Gains_N11: 8 Host
 SG_ KP : 7|32@0+ (1,0) [-3.402823466e+38|3.402823466e+38] "" Driver11
 SG_ KD : 39|32@0+ (1,0) [-3.402823466e+38|3.402823466e+38] "" Driver11

BO_ 1442 Send_Current_Gains_N11: 8 Host
 SG_ Kp_iq : 7|32@0+ (1,0) [-3.402823466e+38|3.402823466e+38] "" Driver11
 SG_ Ki_iq : 39|32@0+ (1,0) [-3.402823466e+38|3.402823466e+38] "" Driver11

BO_ 1444 Send_Velocity_Gains_N11: 8 Host
 SG_ Kpv : 7|32@0+ (1,0) [-3.402823466e+38|3.402823466e+38] "" Driver11
 SG_ Kiv : 39|32@0+ (1,0) [-3.402823466e+38|3.402823466e+38] "" Driver11

BO_ 1446 Send_Position_Gains_N11: 4 Host
 SG_ Kpp : 7|32@0+ (1,0) [-3.402823466e+38|3.402823466e+38] "" Driver11

BO_ 1448 Send_Limits_N11: 8 Host
 SG_ Speed_limit : 7|32@0+ (1,0) [-3.402823466e+38|3.402823466e+38] "" Driver11
 SG_ Current_limit : 39|32@0+ (1,0) [-3.402823466e+38|3.402823466e+38] "" Driver11

BO_ 1452 Send_Kt_N11: 4 Host
 SG_ Kt : 7|32@0+ (1,0) [-3.402823466e+38|3.402823466e+38] "" Driver11

BO_ 1476 Send_Voltage_Limit_N11: 4 Host
 SG_ Voltage_limit : 7|32@0- (1,0) [-2147483648|2147483647] "" Driver11

BO_ 1428 Send_Respond_Ping_N11: 0 Driver11

BO_ 1429 Send_Respond_Ping_N11_Fault: 0 Driver11

BO_ 1454 Send_Respond_Temperature_N11: 2 Driver11
 SG_ temperature : 7|16@0- (1,0) [-32768|32767] "" Host

BO_ 1455 Send_Respond_Temperatu_N11_Fault: 2 Driver11
 SG_ temperature : 7|16@0- (1,0) [-32768|32767] "" Host

BO_ 1456 Send_Respond_Voltage_N11: 2 Driver11
 SG_ voltage : 7|16@0+ (1,0) [0|65535] "" Host

BO_ 1457 Send_Respond_Voltage_N11_Fault: 2 Driver11
 SG_ voltage : 7|16@0+ (1,0) [0|65535] "" Host

BO_ 1458 Send_Respond_Device_Info_N11: 7 Driver11
 SG_ HARDWARE_VERSION : 7|8@0+ (1,0) [0|255] "" Host
 SG_ BATCH_DATE : 15|8@0+ (1,0) [0|255] "" Host
 SG_ SOFTWARE_VERSION : 23|8@0+ (1,0) [0|255] "" Host
 SG_ SERIAL_NUMBER : 31|32@0+ (1,0) [0|4294967295] "" Host

BO_ 1459 Send_Respond_Device_In_N11_Fault: 7 Driver11
 SG_ HARDWARE_VERSION : 7|8@0+ (1,0) [0|255] "" Host
 SG_ BATCH_DATE : 15|8@0+ (1,0) [0|255] "" Host
 SG_ SOFTWARE_VERSION : 23|8@0+ (1,0) [0|255] "" Host
 SG_ SERIAL_NUMBER : 31|32@0+ (1,0) [0|4294967295] "" Host

BO_ 1460 Send_Respond_State_of_Errors_N11: 2 Driver11
 SG_ error : 7|1@0+ (1,0) [0|1] "" Host
 SG_ temperature_error : 6|1@0+ (1,0) [0|1] "" Host
 SG_ encoder_error : 5|1@0+ (1,0) [0|1] "" Host
 SG_ vbus_error : 4|1@0+ (1,0) [0|1] "" Host
 SG_ driver_error : 3|1@0+ (1,0) [0|1] "" Host
 SG_ velocity_error : 2|1@0+ (1,0) [0|1] "" Host
 SG_ current_error : 1|1@0+ (1,0) [0|1] "" Host
 SG_ estop_error : 0|1@0+ (1,0) [0|1] "" Host
 SG_ calibrated : 15|1@0+ (1,0) [0|1] "" Host
 SG_ activated : 14|1@0+ (1,0) [0|1] "" Host
 SG_ watchdog_error : 13|1@0+ (1,0) [0|1] "" Host

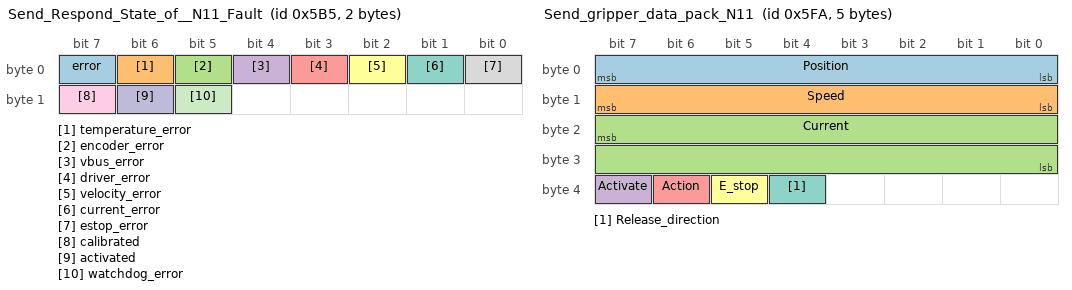
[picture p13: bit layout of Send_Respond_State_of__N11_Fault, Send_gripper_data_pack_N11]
BO_ 1461 Send_Respond_State_of__N11_Fault: 2 Driver11
 SG_ error : 7|1@0+ (1,0) [0|1] "" Host
 SG_ temperature_error : 6|1@0+ (1,0) [0|1] "" Host
 SG_ encoder_error : 5|1@0+ (1,0) [0|1] "" Host
 SG_ vbus_error : 4|1@0+ (1,0) [0|1] "" Host
 SG_ driver_error : 3|1@0+ (1,0) [0|1] "" Host
 SG_ velocity_error : 2|1@0+ (1,0) [0|1] "" Host
 SG_ current_error : 1|1@0+ (1,0) [0|1] "" Host
 SG_ estop_error : 0|1@0+ (1,0) [0|1] "" Host
 SG_ calibrated : 15|1@0+ (1,0) [0|1] "" Host
 SG_ activated : 14|1@0+ (1,0) [0|1] "" Host
 SG_ watchdog_error : 13|1@0+ (1,0) [0|1] "" Host

BO_ 1462 Send_Respond_Iq_data_N11: 2 Driver11
 SG_ current : 7|16@0- (1,0) [-32768|32767] "" Host

BO_ 1463 Send_Respond_Iq_data_N11_Fault: 2 Driver11
 SG_ current : 7|16@0- (1,0) [-32768|32767] "" Host

BO_ 1464 Send_Respond_Encoder_data_N11: 8 Driver11
 SG_ position : 7|32@0- (1,0) [-2147483648|2147483647] "" Host
 SG_ speed : 39|32@0- (1,0) [-2147483648|2147483647] "" Host

BO_ 1465 Send_Respond_Encoder_d_N11_Fault: 8 Driver11
 SG_ position : 7|32@0- (1,0) [-2147483648|2147483647] "" Host
 SG_ speed : 39|32@0- (1,0) [-2147483648|2147483647] "" Host

BO_ 1474 Send_Respond_Kt_N11: 4 Driver11
 SG_ Kt : 7|32@0+ (1,0) [-3.402823466e+38|3.402823466e+38] "" Host

BO_ 1475 Send_Respond_Kt_N11_Fault: 4 Driver11
 SG_ Kt : 7|32@0+ (1,0) [-3.402823466e+38|3.402823466e+38] "" Host

BO_ 1426 Respond_Heartbeat_N11: 0 Driver11

BO_ 1427 Respond_Heartbeat_N11_Fault: 0 Driver11

BO_ 1430 Send_CAN_ID_N11: 1 Host
 SG_ ID : 7|8@0+ (1,0) [0|255] "" Driver11

BO_ 1408 Send_ESTOP_N11: 0 Host

BO_ 1432 Send_Idle_N11: 0 Host

BO_ 1434 Send_Save_config_N11: 0 Host

BO_ 1436 Send_Reset_N11: 0 Host

BO_ 1410 Send_Clear_Error_N11: 0 Host

BO_ 1438 Send_Watchdog_N11: 5 Host
 SG_ Time : 7|32@0+ (1,0) [0|4294967295] "" Driver11
 SG_ Action : 39|8@0+ (1,0) [0|255] "" Driver11

BO_ 1468 Send_Heartbeat_Setup_N11: 4 Host
 SG_ Interval : 7|32@0+ (1,0) [0|4294967295] "" Driver11

BO_ 1478 Send_Settings_N11: 2 Host
 SG_ Mask : 7|8@0+ (1,0) [0|255] "" Driver11
 SG_ Value : 15|8@0+ (1,0) [0|255] "" Driver11

BO_ 1530 Send_gripper_data_pack_N11: 5 Host
 SG_ Position : 7|8@0+ (1,0) [0|255] "" Driver11
 SG_ Speed : 15|8@0+ (1,0) [0|255] "" Driver11
 SG_ Current : 23|16@0- (1,0) [-32768|32767] "" Driver11
 SG_ Activate : 39|1@0+ (1,0) [0|1] "" Driver11
 SG_ Action : 38|1@0+ (1,0) [0|1] "" Driver11
 SG_ E_stop : 37|1@0+ (1,0) [0|1] "" Driver11
 SG_ Release_direction : 36|1@0+ (1,0) [0|1] "" Driver11

BO_ 1532 Send_gripper_calibrate_N11: 0 Host

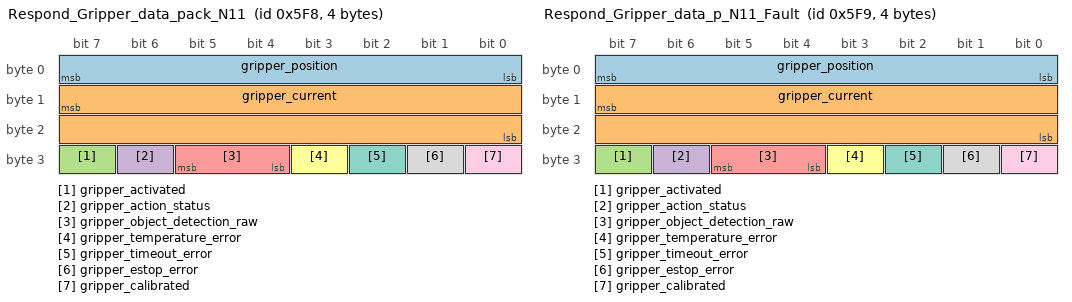
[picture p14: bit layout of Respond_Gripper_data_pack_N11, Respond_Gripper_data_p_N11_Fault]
BO_ 1528 Respond_Gripper_data_pack_N11: 4 Driver11
 SG_ gripper_position : 7|8@0+ (1,0) [0|255] "" Host
 SG_ gripper_current : 15|16@0- (1,0) [-32768|32767] "" Host
 SG_ gripper_activated : 31|1@0+ (1,0) [0|1] "" Host
 SG_ gripper_action_status : 30|1@0+ (1,0) [0|1] "" Host
 SG_ gripper_object_detection_raw : 29|2@0+ (1,0) [0|3] "" Host
 SG_ gripper_temperature_error : 27|1@0+ (1,0) [0|1] "" Host
 SG_ gripper_timeout_error : 26|1@0+ (1,0) [0|1] "" Host
 SG_ gripper_estop_error : 25|1@0+ (1,0) [0|1] "" Host
 SG_ gripper_calibrated : 24|1@0+ (1,0) [0|1] "" Host

BO_ 1529 Respond_Gripper_data_p_N11_Fault: 4 Driver11
 SG_ gripper_position : 7|8@0+ (1,0) [0|255] "" Host
 SG_ gripper_current : 15|16@0- (1,0) [-32768|32767] "" Host
 SG_ gripper_activated : 31|1@0+ (1,0) [0|1] "" Host
 SG_ gripper_action_status : 30|1@0+ (1,0) [0|1] "" Host
 SG_ gripper_object_detection_raw : 29|2@0+ (1,0) [0|3] "" Host
 SG_ gripper_temperature_error : 27|1@0+ (1,0) [0|1] "" Host
 SG_ gripper_timeout_error : 26|1@0+ (1,0) [0|1] "" Host
 SG_ gripper_estop_error : 25|1@0+ (1,0) [0|1] "" Host
 SG_ gripper_calibrated : 24|1@0+ (1,0) [0|1] "" Host

BO_ 1540 Send_data_pack_1_N12: 5 Host
 SG_ Speed_setpoint : 7|24@0- (1,0) [-8388608|8388607] "" Driver12
 SG_ Current_feedforward : 31|16@0- (1,0) [-32768|32767] "" Driver12

BO_ 1544 Send_data_pack_PD_N12: 8 Host
 SG_ Position_setpoint : 7|24@0- (1,0) [-8388608|8388607] "" Driver12
 SG_ Speed_setpoint : 31|24@0- (1,0) [-8388608|8388607] "" Driver12
 SG_ Current_feedforward : 55|16@0- (1,0) [-32768|32767] "" Driver12

BO_ 1598 Send_data_pack_HALL_N12: 4 Host
 SG_ Speed : 7|24@0- (1,0) [-8388608|8388607] "" Driver12
 SG_ Trigger : 31|8@0+ (1,0) [0|255] "" Driver12

BO_ 1542 Respond_data_pack_1_N12: 8 Driver12
 SG_ position : 7|24@0- (1,0) [-8388608|8388607] "" Host
 SG_ speed : 31|24@0- (1,0) [-8388608|8388607] "" Host
 SG_ current : 55|16@0- (1,0) [-32768|32767] "" Host

BO_ 1543 Respond_data_pack_1_N12_Fault: 8 Driver12
 SG_ position : 7|24@0- (1,0) [-8388608|8388607] "" Host
 SG_ speed : 31|24@0- (1,0) [-8388608|8388607] "" Host
 SG_ current : 55|16@0- (1,0) [-32768|32767] "" Host

BO_ 1600 Respond_data_hall_N12: 4 Driver12
 SG_ position : 7|24@0- (1,0) [-8388608|8388607] "" Host
 SG_ HALL_trigger : 31|1@0+ (1,0) [0|1] "" Host
 SG_ additional_pin2 : 30|1@0+ (1,0) [0|1] "" Host
 SG_ hall_index : 29|1@0+ (1,0) [0|1] "" Host

BO_ 1601 Respond_data_hall_N12_Fault: 4 Driver12
 SG_ position : 7|24@0- (1,0) [-8388608|8388607] "" Host
 SG_ HALL_trigger : 31|1@0+ (1,0) [0|1] "" Host
 SG_ additional_pin2 : 30|1@0+ (1,0) [0|1] "" Host
 SG_ hall_index : 29|1@0+ (1,0) [0|1] "" Host

BO_ 1568 Send_PD_Gains_N12: 8 Host
 SG_ KP : 7|32@0+ (1,0) [-3.402823466e+38|3.402823466e+38] "" Driver12
 SG_ KD : 39|32@0+ (1,0) [-3.402823466e+38|3.402823466e+38] "" Driver12

BO_ 1570 Send_Current_Gains_N12: 8 Host
 SG_ Kp_iq : 7|32@0+ (1,0) [-3.402823466e+38|3.402823466e+38] "" Driver12
 SG_ Ki_iq : 39|32@0+ (1,0) [-3.402823466e+38|3.402823466e+38] "" Driver12

BO_ 1572 Send_Velocity_Gains_N12: 8 Host
 SG_ Kpv : 7|32@0+ (1,0) [-3.402823466e+38|3.402823466e+38] "" Driver12
 SG_ Kiv : 39|32@0+ (1,0) [-3.402823466e+38|3.402823466e+38] "" Driver12

BO_ 1574 Send_Position_Gains_N12: 4 Host
 SG_ Kpp : 7|32@0+ (1,0) [-3.402823466e+38|3.402823466e+38] "" Driver12

BO_ 1576 Send_Limits_N12: 8 Host
 SG_ Speed_limit : 7|32@0+ (1,0) [-3.402823466e+38|3.402823466e+38] "" Driver12
 SG_ Current_limit : 39|32@0+ (1,0) [-3.402823466e+38|3.402823466e+38] "" Driver12

BO_ 1580 Send_Kt_N12: 4 Host
 SG_ Kt : 7|32@0+ (1,0) [-3.402823466e+38|3.402823466e+38] "" Driver12

BO_ 1604 Send_Voltage_Limit_N12: 4 Host
 SG_ Voltage_limit : 7|32@0- (1,0) [-2147483648|2147483647] "" Driver12

BO_ 1556 Send_Respond_Ping_N12: 0 Driver12

BO_ 1557 Send_Respond_Ping_N12_Fault: 0 Driver12

BO_ 1582 Send_Respond_Temperature_N12: 2 Driver12
 SG_ temperature : 7|16@0- (1,0) [-32768|32767] "" Host

BO_ 1583 Send_Respond_Temperatu_N12_Fault: 2 Driver12
 SG_ temperature : 7|16@0- (1,0) [-32768|32767] "" Host

BO_ 1584 Send_Respond_Voltage_N12: 2 Driver12
 SG_ voltage : 7|16@0+ (1,0) [0|65535] "" Host

BO_ 1585 Send_Respond_Voltage_N12_Fault: 2 Driver12
 SG_ voltage : 7|16@0+ (1,0) [0|65535] "" Host

BO_ 1586 Send_Respond_Device_Info_N12: 7 Driver12
 SG_ HARDWARE_VERSION : 7|8@0+ (1,0) [0|255] "" Host
 SG_ BATCH_DATE : 15|8@0+ (1,0) [0|255] "" Host
 SG_ SOFTWARE_VERSION : 23|8@0+ (1,0) [0|255] "" Host
 SG_ SERIAL_NUMBER : 31|32@0+ (1,0) [0|4294967295] "" Host

BO_ 1587 Send_Respond_Device_In_N12_Fault: 7 Driver12
 SG_ HARDWARE_VERSION : 7|8@0+ (1,0) [0|255] "" Host
 SG_ BATCH_DATE : 15|8@0+ (1,0) [0|255] "" Host
 SG_ SOFTWARE_VERSION : 23|8@0+ (1,0) [0|255] "" Host
 SG_ SERIAL_NUMBER : 31|32@0+ (1,0) [0|4294967295] "" Host

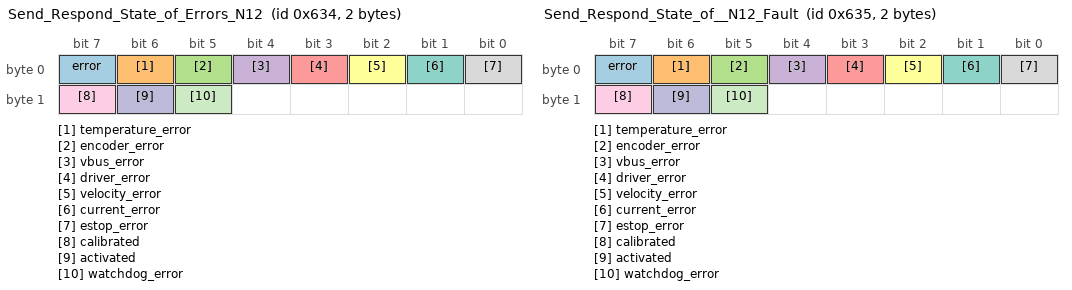
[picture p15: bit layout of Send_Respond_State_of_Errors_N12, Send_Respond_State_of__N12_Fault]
BO_ 1588 Send_Respond_State_of_Errors_N12: 2 Driver12
 SG_ error : 7|1@0+ (1,0) [0|1] "" Host
 SG_ temperature_error : 6|1@0+ (1,0) [0|1] "" Host
 SG_ encoder_error : 5|1@0+ (1,0) [0|1] "" Host
 SG_ vbus_error : 4|1@0+ (1,0) [0|1] "" Host
 SG_ driver_error : 3|1@0+ (1,0) [0|1] "" Host
 SG_ velocity_error : 2|1@0+ (1,0) [0|1] "" Host
 SG_ current_error : 1|1@0+ (1,0) [0|1] "" Host
 SG_ estop_error : 0|1@0+ (1,0) [0|1] "" Host
 SG_ calibrated : 15|1@0+ (1,0) [0|1] "" Host
 SG_ activated : 14|1@0+ (1,0) [0|1] "" Host
 SG_ watchdog_error : 13|1@0+ (1,0) [0|1] "" Host

BO_ 1589 Send_Respond_State_of__N12_Fault: 2 Driver12
 SG_ error : 7|1@0+ (1,0) [0|1] "" Host
 SG_ temperature_error : 6|1@0+ (1,0) [0|1] "" Host
 SG_ encoder_error : 5|1@0+ (1,0) [0|1] "" Host
 SG_ vbus_error : 4|1@0+ (1,0) [0|1] "" Host
 SG_ driver_error : 3|1@0+ (1,0) [0|1] "" Host
 SG_ velocity_error : 2|1@0+ (1,0) [0|1] "" Host
 SG_ current_error : 1|1@0+ (1,0) [0|1] "" Host
 SG_ estop_error : 0|1@0+ (1,0) [0|1] "" Host
 SG_ calibrated : 15|1@0+ (1,0) [0|1] "" Host
 SG_ activated : 14|1@0+ (1,0) [0|1] "" Host
 SG_ watchdog_error : 13|1@0+ (1,0) [0|1] "" Host

BO_ 1590 Send_Respond_Iq_data_N12: 2 Driver12
 SG_ current : 7|16@0- (1,0) [-32768|32767] "" Host

BO_ 1591 Send_Respond_Iq_data_N12_Fault: 2 Driver12
 SG_ current : 7|16@0- (1,0) [-32768|32767] "" Host

BO_ 1592 Send_Respond_Encoder_data_N12: 8 Driver12
 SG_ position : 7|32@0- (1,0) [-2147483648|2147483647] "" Host
 SG_ speed : 39|32@0- (1,0) [-2147483648|2147483647] "" Host

BO_ 1593 Send_Respond_Encoder_d_N12_Fault: 8 Driver12
 SG_ position : 7|32@0- (1,0) [-2147483648|2147483647] "" Host
 SG_ speed : 39|32@0- (1,0) [-2147483648|2147483647] "" Host

BO_ 1602 Send_Respond_Kt_N12: 4 Driver12
 SG_ Kt : 7|32@0+ (1,0) [-3.402823466e+38|3.402823466e+38] "" Host

BO_ 1603 Send_Respond_Kt_N12_Fault: 4 Driver12
 SG_ Kt : 7|32@0+ (1,0) [-3.402823466e+38|3.402823466e+38] "" Host

BO_ 1554 Respond_Heartbeat_N12: 0 Driver12

BO_ 1555 Respond_Heartbeat_N12_Fault: 0 Driver12

BO_ 1558 Send_CAN_ID_N12: 1 Host
 SG_ ID : 7|8@0+ (1,0) [0|255] "" Driver12

BO_ 1536 Send_ESTOP_N12: 0 Host

BO_ 1560 Send_Idle_N12: 0 Host

BO_ 1562 Send_Save_config_N12: 0 Host

BO_ 1564 Send_Reset_N12: 0 Host

BO_ 1538 Send_Clear_Error_N12: 0 Host

BO_ 1566 Send_Watchdog_N12: 5 Host
 SG_ Time : 7|32@0+ (1,0) [0|4294967295] "" Driver12
 SG_ Action : 39|8@0+ (1,0) [0|255] "" Driver12

BO_ 1596 Send_Heartbeat_Setup_N12: 4 Host
 SG_ Interval : 7|32@0+ (1,0) [0|4294967295] "" Driver12

BO_ 1606 Send_Settings_N12: 2 Host
 SG_ Mask : 7|8@0+ (1,0) [0|255] "" Driver12
 SG_ Value : 15|8@0+ (1,0) [0|255] "" Driver12

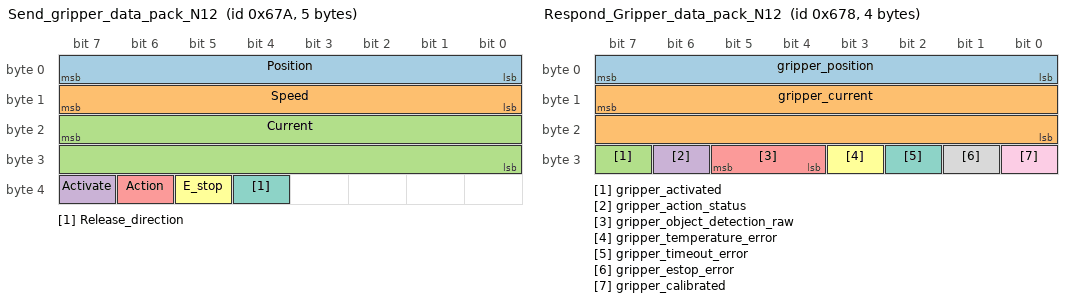
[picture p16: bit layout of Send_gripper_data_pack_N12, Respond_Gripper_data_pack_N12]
BO_ 1658 Send_gripper_data_pack_N12: 5 Host
 SG_ Position : 7|8@0+ (1,0) [0|255] "" Driver12
 SG_ Speed : 15|8@0+ (1,0) [0|255] "" Driver12
 SG_ Current : 23|16@0- (1,0) [-32768|32767] "" Driver12
 SG_ Activate : 39|1@0+ (1,0) [0|1] "" Driver12
 SG_ Action : 38|1@0+ (1,0) [0|1] "" Driver12
 SG_ E_stop : 37|1@0+ (1,0) [0|1] "" Driver12
 SG_ Release_direction : 36|1@0+ (1,0) [0|1] "" Driver12

BO_ 1660 Send_gripper_calibrate_N12: 0 Host

BO_ 1656 Respond_Gripper_data_pack_N12: 4 Driver12
 SG_ gripper_position : 7|8@0+ (1,0) [0|255] "" Host
 SG_ gripper_current : 15|16@0- (1,0) [-32768|32767] "" Host
 SG_ gripper_activated : 31|1@0+ (1,0) [0|1] "" Host
 SG_ gripper_action_status : 30|1@0+ (1,0) [0|1] "" Host
 SG_ gripper_object_detection_raw : 29|2@0+ (1,0) [0|3] "" Host
 SG_ gripper_temperature_error : 27|1@0+ (1,0) [0|1] "" Host
 SG_ gripper_timeout_error : 26|1@0+ (1,0) [0|1] "" Host
 SG_ gripper_estop_error : 25|1@0+ (1,0) [0|1] "" Host
 SG_ gripper_calibrated : 24|1@0+ (1,0) [0|1] "" Host

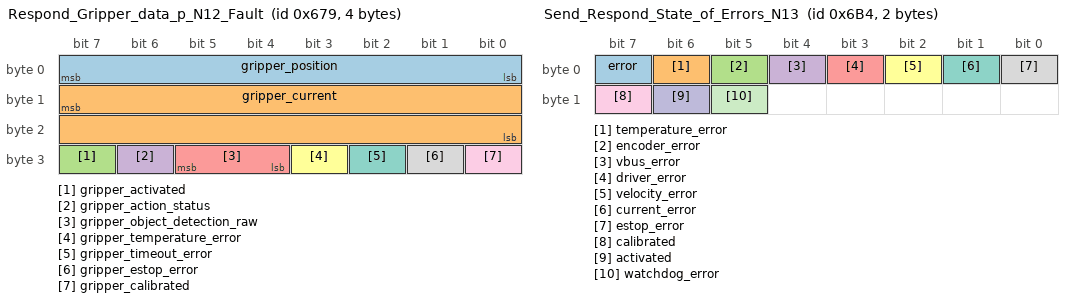
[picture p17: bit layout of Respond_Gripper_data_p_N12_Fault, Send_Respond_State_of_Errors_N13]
BO_ 1657 Respond_Gripper_data_p_N12_Fault: 4 Driver12
 SG_ gripper_position : 7|8@0+ (1,0) [0|255] "" Host
 SG_ gripper_current : 15|16@0- (1,0) [-32768|32767] "" Host
 SG_ gripper_activated : 31|1@0+ (1,0) [0|1] "" Host
 SG_ gripper_action_status : 30|1@0+ (1,0) [0|1] "" Host
 SG_ gripper_object_detection_raw : 29|2@0+ (1,0) [0|3] "" Host
 SG_ gripper_temperature_error : 27|1@0+ (1,0) [0|1] "" Host
 SG_ gripper_timeout_error : 26|1@0+ (1,0) [0|1] "" Host
 SG_ gripper_estop_error : 25|1@0+ (1,0) [0|1] "" Host
 SG_ gripper_calibrated : 24|1@0+ (1,0) [0|1] "" Host

BO_ 1668 Send_data_pack_1_N13: 5 Host
 SG_ Speed_setpoint : 7|24@0- (1,0) [-8388608|8388607] "" Driver13
 SG_ Current_feedforward : 31|16@0- (1,0) [-32768|32767] "" Driver13

BO_ 1672 Send_data_pack_PD_N13: 8 Host
 SG_ Position_setpoint : 7|24@0- (1,0) [-8388608|8388607] "" Driver13
 SG_ Speed_setpoint : 31|24@0- (1,0) [-8388608|8388607] "" Driver13
 SG_ Current_feedforward : 55|16@0- (1,0) [-32768|32767] "" Driver13

BO_ 1726 Send_data_pack_HALL_N13: 4 Host
 SG_ Speed : 7|24@0- (1,0) [-8388608|8388607] "" Driver13
 SG_ Trigger : 31|8@0+ (1,0) [0|255] "" Driver13

BO_ 1670 Respond_data_pack_1_N13: 8 Driver13
 SG_ position : 7|24@0- (1,0) [-8388608|8388607] "" Host
 SG_ speed : 31|24@0- (1,0) [-8388608|8388607] "" Host
 SG_ current : 55|16@0- (1,0) [-32768|32767] "" Host

BO_ 1671 Respond_data_pack_1_N13_Fault: 8 Driver13
 SG_ position : 7|24@0- (1,0) [-8388608|8388607] "" Host
 SG_ speed : 31|24@0- (1,0) [-8388608|8388607] "" Host
 SG_ current : 55|16@0- (1,0) [-32768|32767] "" Host

BO_ 1728 Respond_data_hall_N13: 4 Driver13
 SG_ position : 7|24@0- (1,0) [-8388608|8388607] "" Host
 SG_ HALL_trigger : 31|1@0+ (1,0) [0|1] "" Host
 SG_ additional_pin2 : 30|1@0+ (1,0) [0|1] "" Host
 SG_ hall_index : 29|1@0+ (1,0) [0|1] "" Host

BO_ 1729 Respond_data_hall_N13_Fault: 4 Driver13
 SG_ position : 7|24@0- (1,0) [-8388608|8388607] "" Host
 SG_ HALL_trigger : 31|1@0+ (1,0) [0|1] "" Host
 SG_ additional_pin2 : 30|1@0+ (1,0) [0|1] "" Host
 SG_ hall_index : 29|1@0+ (1,0) [0|1] "" Host

BO_ 1696 Send_PD_Gains_N13: 8 Host
 SG_ KP : 7|32@0+ (1,0) [-3.402823466e+38|3.402823466e+38] "" Driver13
 SG_ KD : 39|32@0+ (1,0) [-3.402823466e+38|3.402823466e+38] "" Driver13

BO_ 1698 Send_Current_Gains_N13: 8 Host
 SG_ Kp_iq : 7|32@0+ (1,0) [-3.402823466e+38|3.402823466e+38] "" Driver13
 SG_ Ki_iq : 39|32@0+ (1,0) [-3.402823466e+38|3.402823466e+38] "" Driver13

BO_ 1700 Send_Velocity_Gains_N13: 8 Host
 SG_ Kpv : 7|32@0+ (1,0) [-3.402823466e+38|3.402823466e+38] "" Driver13
 SG_ Kiv : 39|32@0+ (1,0) [-3.402823466e+38|3.402823466e+38] "" Driver13

BO_ 1702 Send_Position_Gains_N13: 4 Host
 SG_ Kpp : 7|32@0+ (1,0) [-3.402823466e+38|3.402823466e+38] "" Driver13

BO_ 1704 Send_Limits_N13: 8 Host
 SG_ Speed_limit : 7|32@0+ (1,0) [-3.402823466e+38|3.402823466e+38] "" Driver13
 SG_ Current_limit : 39|32@0+ (1,0) [-3.402823466e+38|3.402823466e+38] "" Driver13

BO_ 1708 Send_Kt_N13: 4 Host
 SG_ Kt : 7|32@0+ (1,0) [-3.402823466e+38|3.402823466e+38] "" Driver13

BO_ 1732 Send_Voltage_Limit_N13: 4 Host
 SG_ Voltage_limit : 7|32@0- (1,0) [-2147483648|2147483647] "" Driver13

BO_ 1684 Send_Respond_Ping_N13: 0 Driver13

BO_ 1685 Send_Respond_Ping_N13_Fault: 0 Driver13

BO_ 1710 Send_Respond_Temperature_N13: 2 Driver13
 SG_ temperature : 7|16@0- (1,0) [-32768|32767] "" Host

BO_ 1711 Send_Respond_Temperatu_N13_Fault: 2 Driver13
 SG_ temperature : 7|16@0- (1,0) [-32768|32767] "" Host

BO_ 1712 Send_Respond_Voltage_N13: 2 Driver13
 SG_ voltage : 7|16@0+ (1,0) [0|65535] "" Host

BO_ 1713 Send_Respond_Voltage_N13_Fault: 2 Driver13
 SG_ voltage : 7|16@0+ (1,0) [0|65535] "" Host

BO_ 1714 Send_Respond_Device_Info_N13: 7 Driver13
 SG_ HARDWARE_VERSION : 7|8@0+ (1,0) [0|255] "" Host
 SG_ BATCH_DATE : 15|8@0+ (1,0) [0|255] "" Host
 SG_ SOFTWARE_VERSION : 23|8@0+ (1,0) [0|255] "" Host
 SG_ SERIAL_NUMBER : 31|32@0+ (1,0) [0|4294967295] "" Host

BO_ 1715 Send_Respond_Device_In_N13_Fault: 7 Driver13
 SG_ HARDWARE_VERSION : 7|8@0+ (1,0) [0|255] "" Host
 SG_ BATCH_DATE : 15|8@0+ (1,0) [0|255] "" Host
 SG_ SOFTWARE_VERSION : 23|8@0+ (1,0) [0|255] "" Host
 SG_ SERIAL_NUMBER : 31|32@0+ (1,0) [0|4294967295] "" Host

BO_ 1716 Send_Respond_State_of_Errors_N13: 2 Driver13
 SG_ error : 7|1@0+ (1,0) [0|1] "" Host
 SG_ temperature_error : 6|1@0+ (1,0) [0|1] "" Host
 SG_ encoder_error : 5|1@0+ (1,0) [0|1] "" Host
 SG_ vbus_error : 4|1@0+ (1,0) [0|1] "" Host
 SG_ driver_error : 3|1@0+ (1,0) [0|1] "" Host
 SG_ velocity_error : 2|1@0+ (1,0) [0|1] "" Host
 SG_ current_error : 1|1@0+ (1,0) [0|1] "" Host
 SG_ estop_error : 0|1@0+ (1,0) [0|1] "" Host
 SG_ calibrated : 15|1@0+ (1,0) [0|1] "" Host
 SG_ activated : 14|1@0+ (1,0) [0|1] "" Host
 SG_ watchdog_error : 13|1@0+ (1,0) [0|1] "" Host

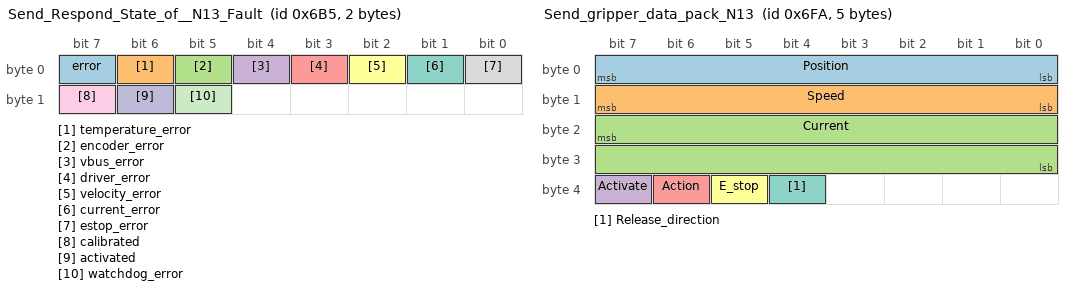
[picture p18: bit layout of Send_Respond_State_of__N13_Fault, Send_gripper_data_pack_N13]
BO_ 1717 Send_Respond_State_of__N13_Fault: 2 Driver13
 SG_ error : 7|1@0+ (1,0) [0|1] "" Host
 SG_ temperature_error : 6|1@0+ (1,0) [0|1] "" Host
 SG_ encoder_error : 5|1@0+ (1,0) [0|1] "" Host
 SG_ vbus_error : 4|1@0+ (1,0) [0|1] "" Host
 SG_ driver_error : 3|1@0+ (1,0) [0|1] "" Host
 SG_ velocity_error : 2|1@0+ (1,0) [0|1] "" Host
 SG_ current_error : 1|1@0+ (1,0) [0|1] "" Host
 SG_ estop_error : 0|1@0+ (1,0) [0|1] "" Host
 SG_ calibrated : 15|1@0+ (1,0) [0|1] "" Host
 SG_ activated : 14|1@0+ (1,0) [0|1] "" Host
 SG_ watchdog_error : 13|1@0+ (1,0) [0|1] "" Host

BO_ 1718 Send_Respond_Iq_data_N13: 2 Driver13
 SG_ current : 7|16@0- (1,0) [-32768|32767] "" Host

BO_ 1719 Send_Respond_Iq_data_N13_Fault: 2 Driver13
 SG_ current : 7|16@0- (1,0) [-32768|32767] "" Host

BO_ 1720 Send_Respond_Encoder_data_N13: 8 Driver13
 SG_ position : 7|32@0- (1,0) [-2147483648|2147483647] "" Host
 SG_ speed : 39|32@0- (1,0) [-2147483648|2147483647] "" Host

BO_ 1721 Send_Respond_Encoder_d_N13_Fault: 8 Driver13
 SG_ position : 7|32@0- (1,0) [-2147483648|2147483647] "" Host
 SG_ speed : 39|32@0- (1,0) [-2147483648|2147483647] "" Host

BO_ 1730 Send_Respond_Kt_N13: 4 Driver13
 SG_ Kt : 7|32@0+ (1,0) [-3.402823466e+38|3.402823466e+38] "" Host

BO_ 1731 Send_Respond_Kt_N13_Fault: 4 Driver13
 SG_ Kt : 7|32@0+ (1,0) [-3.402823466e+38|3.402823466e+38] "" Host

BO_ 1682 Respond_Heartbeat_N13: 0 Driver13

BO_ 1683 Respond_Heartbeat_N13_Fault: 0 Driver13

BO_ 1686 Send_CAN_ID_N13: 1 Host
 SG_ ID : 7|8@0+ (1,0) [0|255] "" Driver13

BO_ 1664 Send_ESTOP_N13: 0 Host

BO_ 1688 Send_Idle_N13: 0 Host

BO_ 1690 Send_Save_config_N13: 0 Host

BO_ 1692 Send_Reset_N13: 0 Host

BO_ 1666 Send_Clear_Error_N13: 0 Host

BO_ 1694 Send_Watchdog_N13: 5 Host
 SG_ Time : 7|32@0+ (1,0) [0|4294967295] "" Driver13
 SG_ Action : 39|8@0+ (1,0) [0|255] "" Driver13

BO_ 1724 Send_Heartbeat_Setup_N13: 4 Host
 SG_ Interval : 7|32@0+ (1,0) [0|4294967295] "" Driver13

BO_ 1734 Send_Settings_N13: 2 Host
 SG_ Mask : 7|8@0+ (1,0) [0|255] "" Driver13
 SG_ Value : 15|8@0+ (1,0) [0|255] "" Driver13

BO_ 1786 Send_gripper_data_pack_N13: 5 Host
 SG_ Position : 7|8@0+ (1,0) [0|255] "" Driver13
 SG_ Speed : 15|8@0+ (1,0) [0|255] "" Driver13
 SG_ Current : 23|16@0- (1,0) [-32768|32767] "" Driver13
 SG_ Activate : 39|1@0+ (1,0) [0|1] "" Driver13
 SG_ Action : 38|1@0+ (1,0) [0|1] "" Driver13
 SG_ E_stop : 37|1@0+ (1,0) [0|1] "" Driver13
 SG_ Release_direction : 36|1@0+ (1,0) [0|1] "" Driver13

BO_ 1788 Send_gripper_calibrate_N13: 0 Host

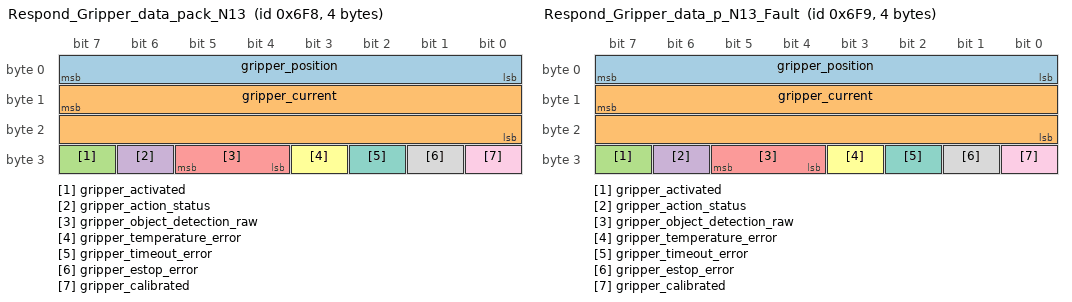
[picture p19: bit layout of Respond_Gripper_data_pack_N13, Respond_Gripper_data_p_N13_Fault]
BO_ 1784 Respond_Gripper_data_pack_N13: 4 Driver13
 SG_ gripper_position : 7|8@0+ (1,0) [0|255] "" Host
 SG_ gripper_current : 15|16@0- (1,0) [-32768|32767] "" Host
 SG_ gripper_activated : 31|1@0+ (1,0) [0|1] "" Host
 SG_ gripper_action_status : 30|1@0+ (1,0) [0|1] "" Host
 SG_ gripper_object_detection_raw : 29|2@0+ (1,0) [0|3] "" Host
 SG_ gripper_temperature_error : 27|1@0+ (1,0) [0|1] "" Host
 SG_ gripper_timeout_error : 26|1@0+ (1,0) [0|1] "" Host
 SG_ gripper_estop_error : 25|1@0+ (1,0) [0|1] "" Host
 SG_ gripper_calibrated : 24|1@0+ (1,0) [0|1] "" Host

BO_ 1785 Respond_Gripper_data_p_N13_Fault: 4 Driver13
 SG_ gripper_position : 7|8@0+ (1,0) [0|255] "" Host
 SG_ gripper_current : 15|16@0- (1,0) [-32768|32767] "" Host
 SG_ gripper_activated : 31|1@0+ (1,0) [0|1] "" Host
 SG_ gripper_action_status : 30|1@0+ (1,0) [0|1] "" Host
 SG_ gripper_object_detection_raw : 29|2@0+ (1,0) [0|3] "" Host
 SG_ gripper_temperature_error : 27|1@0+ (1,0) [0|1] "" Host
 SG_ gripper_timeout_error : 26|1@0+ (1,0) [0|1] "" Host
 SG_ gripper_estop_error : 25|1@0+ (1,0) [0|1] "" Host
 SG_ gripper_calibrated : 24|1@0+ (1,0) [0|1] "" Host

CM_ SG_ 958 Speed "encoder ticks/s; the sign gives the direction";
CM_ SG_ 958 Trigger "0 = trigger when the pin is low, 1 = when it is high, 2 = on any edge";
CM_ SG_ 902 position "encoder ticks";
CM_ SG_ 902 speed "encoder ticks/s";
CM_ SG_ 902 current "Iq in mA";
CM_ SG_ 903 position "encoder ticks";
CM_ SG_ 903 speed "encoder ticks/s";
CM_ SG_ 903 current "Iq in mA";
CM_ SG_ 960 position "encoder ticks";
CM_ SG_ 960 HALL_trigger "1 while the driver waits for the trigger (with a level trigger, also again after the pin left the level), 0 while it holds";
CM_ SG_ 960 additional_pin2 "the raw level of the ADDITIONAL2 pin";
CM_ SG_ 960 hall_index "1 once the trigger has been seen (latched)";
CM_ SG_ 961 position "encoder ticks";
CM_ SG_ 961 HALL_trigger "1 while the driver waits for the trigger (with a level trigger, also again after the pin left the level), 0 while it holds";
CM_ SG_ 961 additional_pin2 "the raw level of the ADDITIONAL2 pin";
CM_ SG_ 961 hall_index "1 once the trigger has been seen (latched)";
CM_ SG_ 936 Speed_limit "encoder ticks/s";
CM_ SG_ 936 Current_limit "mA";
CM_ SG_ 940 Kt "Nm/A";
CM_ SG_ 964 Voltage_limit "mV; 0 = Vbus";
CM_ SG_ 942 temperature "\u00b0C";
CM_ SG_ 943 temperature "\u00b0C";
CM_ SG_ 944 voltage "mV";
CM_ SG_ 945 voltage "mV";
CM_ SG_ 946 HARDWARE_VERSION "PCB revision";
CM_ SG_ 946 BATCH_DATE "production batch";
CM_ SG_ 946 SOFTWARE_VERSION "firmware release, e.g. 108";
CM_ SG_ 946 SERIAL_NUMBER "serial number as held in RAM: 1 after a power-up";
CM_ SG_ 947 HARDWARE_VERSION "PCB revision";
CM_ SG_ 947 BATCH_DATE "production batch";
CM_ SG_ 947 SOFTWARE_VERSION "firmware release, e.g. 108";
CM_ SG_ 947 SERIAL_NUMBER "serial number as held in RAM: 1 after a power-up";
CM_ SG_ 948 error "any error is active";
CM_ SG_ 948 temperature_error "motor over the temperature limit";
CM_ SG_ 948 encoder_error "the encoder reports no magnet (too weak a field)";
CM_ SG_ 948 vbus_error "supply voltage outside the limits";
CM_ SG_ 948 driver_error "reserved; never set by this firmware (STEPFOC does not read a fault output of its driver stage)";
CM_ SG_ 948 velocity_error "speed above 30,000,000 ticks/s, a fixed threshold (not #Vlimit)";
CM_ SG_ 948 current_error "reserved; never set by this firmware";
CM_ SG_ 948 estop_error "Send_ESTOP was received";
CM_ SG_ 948 calibrated "the motor is calibrated";
CM_ SG_ 948 activated "the controller is activated";
CM_ SG_ 948 watchdog_error "the watchdog ran out";
CM_ SG_ 949 error "any error is active";
CM_ SG_ 949 temperature_error "motor over the temperature limit";
CM_ SG_ 949 encoder_error "the encoder reports no magnet (too weak a field)";
CM_ SG_ 949 vbus_error "supply voltage outside the limits";
CM_ SG_ 949 driver_error "reserved; never set by this firmware (STEPFOC does not read a fault output of its driver stage)";
CM_ SG_ 949 velocity_error "speed above 30,000,000 ticks/s, a fixed threshold (not #Vlimit)";
CM_ SG_ 949 current_error "reserved; never set by this firmware";
CM_ SG_ 949 estop_error "Send_ESTOP was received";
CM_ SG_ 949 calibrated "the motor is calibrated";
CM_ SG_ 949 activated "the controller is activated";
CM_ SG_ 949 watchdog_error "the watchdog ran out";
CM_ SG_ 950 current "mA";
CM_ SG_ 951 current "mA";
CM_ SG_ 952 position "encoder ticks";
CM_ SG_ 952 speed "encoder ticks/s";
CM_ SG_ 953 position "encoder ticks";
CM_ SG_ 953 speed "encoder ticks/s";
CM_ SG_ 962 Kt "Nm/A";
CM_ SG_ 963 Kt "Nm/A";
CM_ SG_ 918 ID "0 to 13; 14 and 15 are accepted but reserved by the bootloader";
CM_ SG_ 926 Time "ms; 0 = off";
CM_ SG_ 926 Action "0 idle, 1 hold, 2 brake (stored only)";
CM_ SG_ 956 Interval "ms; 0 = off";
CM_ SG_ 966 Mask "bit 0 = write the idle behaviour";
CM_ SG_ 966 Value "bit 0: 1 brake, 0 coast";
CM_ SG_ 1018 Position "0 fully open, 255 fully closed";
CM_ SG_ 1018 Speed "0 slowest, 255 fastest";
CM_ SG_ 1018 Current "current limit of the move in mA; not clamped by the firmware, not even to the driver's 2800 mA; see the gripper manual for the safe range";
CM_ SG_ 1018 Activate "1 activate the gripper, 0 deactivate";
CM_ SG_ 1018 Action "1 go to the position, 0 idle";
CM_ SG_ 1018 E_stop "1 raises the gripper E-stop error, again on every control cycle until a frame with this bit 0 arrives; then Send_Clear_Error";
CM_ SG_ 1018 Release_direction "read by the firmware but not used";
CM_ SG_ 1016 gripper_position "0 fully open, 255 fully closed";
CM_ SG_ 1016 gripper_current "measured current in mA";
CM_ SG_ 1016 gripper_activated "1 activated";
CM_ SG_ 1016 gripper_action_status "the action bit of the last Send_gripper_data_pack (1 after #Grippos); the driver never clears it, so it stays 1 after the move ends: the object detection tells when the move has ended";
CM_ SG_ 1016 gripper_object_detection_raw "bit 5 is the low bit, bit 4 the high bit: 0 moving, 1 object detected while closing, 2 object detected while opening, 3 at the position; raw bit pair, see value labels (wire order differs from numeric status)";
CM_ SG_ 1016 gripper_temperature_error "a copy of the thermistor temperature error";
CM_ SG_ 1016 gripper_timeout_error "a copy of the CAN watchdog error (Send_Watchdog), not a move timeout";
CM_ SG_ 1016 gripper_estop_error "the E-stop bit of Send_gripper_data_pack (or #Gripstop 1) was set";
CM_ SG_ 1016 gripper_calibrated "1 calibrated";
CM_ SG_ 1017 gripper_position "0 fully open, 255 fully closed";
CM_ SG_ 1017 gripper_current "measured current in mA";
CM_ SG_ 1017 gripper_activated "1 activated";
CM_ SG_ 1017 gripper_action_status "the action bit of the last Send_gripper_data_pack (1 after #Grippos); the driver never clears it, so it stays 1 after the move ends: the object detection tells when the move has ended";
CM_ SG_ 1017 gripper_object_detection_raw "bit 5 is the low bit, bit 4 the high bit: 0 moving, 1 object detected while closing, 2 object detected while opening, 3 at the position; raw bit pair, see value labels (wire order differs from numeric status)";
CM_ SG_ 1017 gripper_temperature_error "a copy of the thermistor temperature error";
CM_ SG_ 1017 gripper_timeout_error "a copy of the CAN watchdog error (Send_Watchdog), not a move timeout";
CM_ SG_ 1017 gripper_estop_error "the E-stop bit of Send_gripper_data_pack (or #Gripstop 1) was set";
CM_ SG_ 1017 gripper_calibrated "1 calibrated";
CM_ SG_ 1028 Speed_setpoint "encoder ticks/s";
CM_ SG_ 1028 Current_feedforward "mA";
CM_ SG_ 1032 Position_setpoint "encoder ticks";
CM_ SG_ 1032 Speed_setpoint "encoder ticks/s";
CM_ SG_ 1032 Current_feedforward "mA";
CM_ SG_ 1086 Speed "encoder ticks/s; the sign gives the direction";
CM_ SG_ 1086 Trigger "0 = trigger when the pin is low, 1 = when it is high, 2 = on any edge";
CM_ SG_ 1030 position "encoder ticks";
CM_ SG_ 1030 speed "encoder ticks/s";
CM_ SG_ 1030 current "Iq in mA";
CM_ SG_ 1031 position "encoder ticks";
CM_ SG_ 1031 speed "encoder ticks/s";
CM_ SG_ 1031 current "Iq in mA";
CM_ SG_ 1088 position "encoder ticks";
CM_ SG_ 1088 HALL_trigger "1 while the driver waits for the trigger (with a level trigger, also again after the pin left the level), 0 while it holds";
CM_ SG_ 1088 additional_pin2 "the raw level of the ADDITIONAL2 pin";
CM_ SG_ 1088 hall_index "1 once the trigger has been seen (latched)";
CM_ SG_ 1089 position "encoder ticks";
CM_ SG_ 1089 HALL_trigger "1 while the driver waits for the trigger (with a level trigger, also again after the pin left the level), 0 while it holds";
CM_ SG_ 1089 additional_pin2 "the raw level of the ADDITIONAL2 pin";
CM_ SG_ 1089 hall_index "1 once the trigger has been seen (latched)";
CM_ SG_ 1064 Speed_limit "encoder ticks/s";
CM_ SG_ 1064 Current_limit "mA";
CM_ SG_ 1068 Kt "Nm/A";
CM_ SG_ 1092 Voltage_limit "mV; 0 = Vbus";
CM_ SG_ 1070 temperature "\u00b0C";
CM_ SG_ 1071 temperature "\u00b0C";
CM_ SG_ 1072 voltage "mV";
CM_ SG_ 1073 voltage "mV";
CM_ SG_ 1074 HARDWARE_VERSION "PCB revision";
CM_ SG_ 1074 BATCH_DATE "production batch";
CM_ SG_ 1074 SOFTWARE_VERSION "firmware release, e.g. 108";
CM_ SG_ 1074 SERIAL_NUMBER "serial number as held in RAM: 1 after a power-up";
CM_ SG_ 1075 HARDWARE_VERSION "PCB revision";
CM_ SG_ 1075 BATCH_DATE "production batch";
CM_ SG_ 1075 SOFTWARE_VERSION "firmware release, e.g. 108";
CM_ SG_ 1075 SERIAL_NUMBER "serial number as held in RAM: 1 after a power-up";
CM_ SG_ 1076 error "any error is active";
CM_ SG_ 1076 temperature_error "motor over the temperature limit";
CM_ SG_ 1076 encoder_error "the encoder reports no magnet (too weak a field)";
CM_ SG_ 1076 vbus_error "supply voltage outside the limits";
CM_ SG_ 1076 driver_error "reserved; never set by this firmware (STEPFOC does not read a fault output of its driver stage)";
CM_ SG_ 1076 velocity_error "speed above 30,000,000 ticks/s, a fixed threshold (not #Vlimit)";
CM_ SG_ 1076 current_error "reserved; never set by this firmware";
CM_ SG_ 1076 estop_error "Send_ESTOP was received";
CM_ SG_ 1076 calibrated "the motor is calibrated";
CM_ SG_ 1076 activated "the controller is activated";
CM_ SG_ 1076 watchdog_error "the watchdog ran out";
CM_ SG_ 1077 error "any error is active";
CM_ SG_ 1077 temperature_error "motor over the temperature limit";
CM_ SG_ 1077 encoder_error "the encoder reports no magnet (too weak a field)";
CM_ SG_ 1077 vbus_error "supply voltage outside the limits";
CM_ SG_ 1077 driver_error "reserved; never set by this firmware (STEPFOC does not read a fault output of its driver stage)";
CM_ SG_ 1077 velocity_error "speed above 30,000,000 ticks/s, a fixed threshold (not #Vlimit)";
CM_ SG_ 1077 current_error "reserved; never set by this firmware";
CM_ SG_ 1077 estop_error "Send_ESTOP was received";
CM_ SG_ 1077 calibrated "the motor is calibrated";
CM_ SG_ 1077 activated "the controller is activated";
CM_ SG_ 1077 watchdog_error "the watchdog ran out";
CM_ SG_ 1078 current "mA";
CM_ SG_ 1079 current "mA";
CM_ SG_ 1080 position "encoder ticks";
CM_ SG_ 1080 speed "encoder ticks/s";
CM_ SG_ 1081 position "encoder ticks";
CM_ SG_ 1081 speed "encoder ticks/s";
CM_ SG_ 1090 Kt "Nm/A";
CM_ SG_ 1091 Kt "Nm/A";
CM_ SG_ 1046 ID "0 to 13; 14 and 15 are accepted but reserved by the bootloader";
CM_ SG_ 1054 Time "ms; 0 = off";
CM_ SG_ 1054 Action "0 idle, 1 hold, 2 brake (stored only)";
CM_ SG_ 1084 Interval "ms; 0 = off";
CM_ SG_ 1094 Mask "bit 0 = write the idle behaviour";
CM_ SG_ 1094 Value "bit 0: 1 brake, 0 coast";
CM_ SG_ 1146 Position "0 fully open, 255 fully closed";
CM_ SG_ 1146 Speed "0 slowest, 255 fastest";
CM_ SG_ 1146 Current "current limit of the move in mA; not clamped by the firmware, not even to the driver's 2800 mA; see the gripper manual for the safe range";
CM_ SG_ 1146 Activate "1 activate the gripper, 0 deactivate";
CM_ SG_ 1146 Action "1 go to the position, 0 idle";
CM_ SG_ 1146 E_stop "1 raises the gripper E-stop error, again on every control cycle until a frame with this bit 0 arrives; then Send_Clear_Error";
CM_ SG_ 1146 Release_direction "read by the firmware but not used";
CM_ SG_ 1144 gripper_position "0 fully open, 255 fully closed";
CM_ SG_ 1144 gripper_current "measured current in mA";
CM_ SG_ 1144 gripper_activated "1 activated";
CM_ SG_ 1144 gripper_action_status "the action bit of the last Send_gripper_data_pack (1 after #Grippos); the driver never clears it, so it stays 1 after the move ends: the object detection tells when the move has ended";
CM_ SG_ 1144 gripper_object_detection_raw "bit 5 is the low bit, bit 4 the high bit: 0 moving, 1 object detected while closing, 2 object detected while opening, 3 at the position; raw bit pair, see value labels (wire order differs from numeric status)";
CM_ SG_ 1144 gripper_temperature_error "a copy of the thermistor temperature error";
CM_ SG_ 1144 gripper_timeout_error "a copy of the CAN watchdog error (Send_Watchdog), not a move timeout";
CM_ SG_ 1144 gripper_estop_error "the E-stop bit of Send_gripper_data_pack (or #Gripstop 1) was set";
CM_ SG_ 1144 gripper_calibrated "1 calibrated";
CM_ SG_ 1145 gripper_position "0 fully open, 255 fully closed";
CM_ SG_ 1145 gripper_current "measured current in mA";
CM_ SG_ 1145 gripper_activated "1 activated";
CM_ SG_ 1145 gripper_action_status "the action bit of the last Send_gripper_data_pack (1 after #Grippos); the driver never clears it, so it stays 1 after the move ends: the object detection tells when the move has ended";
CM_ SG_ 1145 gripper_object_detection_raw "bit 5 is the low bit, bit 4 the high bit: 0 moving, 1 object detected while closing, 2 object detected while opening, 3 at the position; raw bit pair, see value labels (wire order differs from numeric status)";
CM_ SG_ 1145 gripper_temperature_error "a copy of the thermistor temperature error";
CM_ SG_ 1145 gripper_timeout_error "a copy of the CAN watchdog error (Send_Watchdog), not a move timeout";
CM_ SG_ 1145 gripper_estop_error "the E-stop bit of Send_gripper_data_pack (or #Gripstop 1) was set";
CM_ SG_ 1145 gripper_calibrated "1 calibrated";
CM_ SG_ 1156 Speed_setpoint "encoder ticks/s";
CM_ SG_ 1156 Current_feedforward "mA";
CM_ SG_ 1160 Position_setpoint "encoder ticks";
CM_ SG_ 1160 Speed_setpoint "encoder ticks/s";
CM_ SG_ 1160 Current_feedforward "mA";
CM_ SG_ 1214 Speed "encoder ticks/s; the sign gives the direction";
CM_ SG_ 1214 Trigger "0 = trigger when the pin is low, 1 = when it is high, 2 = on any edge";
CM_ SG_ 1158 position "encoder ticks";
CM_ SG_ 1158 speed "encoder ticks/s";
CM_ SG_ 1158 current "Iq in mA";
CM_ SG_ 1159 position "encoder ticks";
CM_ SG_ 1159 speed "encoder ticks/s";
CM_ SG_ 1159 current "Iq in mA";
CM_ SG_ 1216 position "encoder ticks";
CM_ SG_ 1216 HALL_trigger "1 while the driver waits for the trigger (with a level trigger, also again after the pin left the level), 0 while it holds";
CM_ SG_ 1216 additional_pin2 "the raw level of the ADDITIONAL2 pin";
CM_ SG_ 1216 hall_index "1 once the trigger has been seen (latched)";
CM_ SG_ 1217 position "encoder ticks";
CM_ SG_ 1217 HALL_trigger "1 while the driver waits for the trigger (with a level trigger, also again after the pin left the level), 0 while it holds";
CM_ SG_ 1217 additional_pin2 "the raw level of the ADDITIONAL2 pin";
CM_ SG_ 1217 hall_index "1 once the trigger has been seen (latched)";
CM_ SG_ 1192 Speed_limit "encoder ticks/s";
CM_ SG_ 1192 Current_limit "mA";
CM_ SG_ 1196 Kt "Nm/A";
CM_ SG_ 1220 Voltage_limit "mV; 0 = Vbus";
CM_ SG_ 1198 temperature "\u00b0C";
CM_ SG_ 1199 temperature "\u00b0C";
CM_ SG_ 1200 voltage "mV";
CM_ SG_ 1201 voltage "mV";
CM_ SG_ 1202 HARDWARE_VERSION "PCB revision";
CM_ SG_ 1202 BATCH_DATE "production batch";
CM_ SG_ 1202 SOFTWARE_VERSION "firmware release, e.g. 108";
CM_ SG_ 1202 SERIAL_NUMBER "serial number as held in RAM: 1 after a power-up";
CM_ SG_ 1203 HARDWARE_VERSION "PCB revision";
CM_ SG_ 1203 BATCH_DATE "production batch";
CM_ SG_ 1203 SOFTWARE_VERSION "firmware release, e.g. 108";
CM_ SG_ 1203 SERIAL_NUMBER "serial number as held in RAM: 1 after a power-up";
CM_ SG_ 1204 error "any error is active";
CM_ SG_ 1204 temperature_error "motor over the temperature limit";
CM_ SG_ 1204 encoder_error "the encoder reports no magnet (too weak a field)";
CM_ SG_ 1204 vbus_error "supply voltage outside the limits";
CM_ SG_ 1204 driver_error "reserved; never set by this firmware (STEPFOC does not read a fault output of its driver stage)";
CM_ SG_ 1204 velocity_error "speed above 30,000,000 ticks/s, a fixed threshold (not #Vlimit)";
CM_ SG_ 1204 current_error "reserved; never set by this firmware";
CM_ SG_ 1204 estop_error "Send_ESTOP was received";
CM_ SG_ 1204 calibrated "the motor is calibrated";
CM_ SG_ 1204 activated "the controller is activated";
CM_ SG_ 1204 watchdog_error "the watchdog ran out";
CM_ SG_ 1205 error "any error is active";
CM_ SG_ 1205 temperature_error "motor over the temperature limit";
CM_ SG_ 1205 encoder_error "the encoder reports no magnet (too weak a field)";
CM_ SG_ 1205 vbus_error "supply voltage outside the limits";
CM_ SG_ 1205 driver_error "reserved; never set by this firmware (STEPFOC does not read a fault output of its driver stage)";
CM_ SG_ 1205 velocity_error "speed above 30,000,000 ticks/s, a fixed threshold (not #Vlimit)";
CM_ SG_ 1205 current_error "reserved; never set by this firmware";
CM_ SG_ 1205 estop_error "Send_ESTOP was received";
CM_ SG_ 1205 calibrated "the motor is calibrated";
CM_ SG_ 1205 activated "the controller is activated";
CM_ SG_ 1205 watchdog_error "the watchdog ran out";
CM_ SG_ 1206 current "mA";
CM_ SG_ 1207 current "mA";
CM_ SG_ 1208 position "encoder ticks";
CM_ SG_ 1208 speed "encoder ticks/s";
CM_ SG_ 1209 position "encoder ticks";
CM_ SG_ 1209 speed "encoder ticks/s";
CM_ SG_ 1218 Kt "Nm/A";
CM_ SG_ 1219 Kt "Nm/A";
CM_ SG_ 1174 ID "0 to 13; 14 and 15 are accepted but reserved by the bootloader";
CM_ SG_ 1182 Time "ms; 0 = off";
CM_ SG_ 1182 Action "0 idle, 1 hold, 2 brake (stored only)";
CM_ SG_ 1212 Interval "ms; 0 = off";
CM_ SG_ 1222 Mask "bit 0 = write the idle behaviour";
CM_ SG_ 1222 Value "bit 0: 1 brake, 0 coast";
CM_ SG_ 1274 Position "0 fully open, 255 fully closed";
CM_ SG_ 1274 Speed "0 slowest, 255 fastest";
CM_ SG_ 1274 Current "current limit of the move in mA; not clamped by the firmware, not even to the driver's 2800 mA; see the gripper manual for the safe range";
CM_ SG_ 1274 Activate "1 activate the gripper, 0 deactivate";
CM_ SG_ 1274 Action "1 go to the position, 0 idle";
CM_ SG_ 1274 E_stop "1 raises the gripper E-stop error, again on every control cycle until a frame with this bit 0 arrives; then Send_Clear_Error";
CM_ SG_ 1274 Release_direction "read by the firmware but not used";
CM_ SG_ 1272 gripper_position "0 fully open, 255 fully closed";
CM_ SG_ 1272 gripper_current "measured current in mA";
CM_ SG_ 1272 gripper_activated "1 activated";
CM_ SG_ 1272 gripper_action_status "the action bit of the last Send_gripper_data_pack (1 after #Grippos); the driver never clears it, so it stays 1 after the move ends: the object detection tells when the move has ended";
CM_ SG_ 1272 gripper_object_detection_raw "bit 5 is the low bit, bit 4 the high bit: 0 moving, 1 object detected while closing, 2 object detected while opening, 3 at the position; raw bit pair, see value labels (wire order differs from numeric status)";
CM_ SG_ 1272 gripper_temperature_error "a copy of the thermistor temperature error";
CM_ SG_ 1272 gripper_timeout_error "a copy of the CAN watchdog error (Send_Watchdog), not a move timeout";
CM_ SG_ 1272 gripper_estop_error "the E-stop bit of Send_gripper_data_pack (or #Gripstop 1) was set";
CM_ SG_ 1272 gripper_calibrated "1 calibrated";
CM_ SG_ 1273 gripper_position "0 fully open, 255 fully closed";
CM_ SG_ 1273 gripper_current "measured current in mA";
CM_ SG_ 1273 gripper_activated "1 activated";
CM_ SG_ 1273 gripper_action_status "the action bit of the last Send_gripper_data_pack (1 after #Grippos); the driver never clears it, so it stays 1 after the move ends: the object detection tells when the move has ended";
CM_ SG_ 1273 gripper_object_detection_raw "bit 5 is the low bit, bit 4 the high bit: 0 moving, 1 object detected while closing, 2 object detected while opening, 3 at the position; raw bit pair, see value labels (wire order differs from numeric status)";
CM_ SG_ 1273 gripper_temperature_error "a copy of the thermistor temperature error";
CM_ SG_ 1273 gripper_timeout_error "a copy of the CAN watchdog error (Send_Watchdog), not a move timeout";
CM_ SG_ 1273 gripper_estop_error "the E-stop bit of Send_gripper_data_pack (or #Gripstop 1) was set";
CM_ SG_ 1273 gripper_calibrated "1 calibrated";
CM_ SG_ 1284 Speed_setpoint "encoder ticks/s";
CM_ SG_ 1284 Current_feedforward "mA";
CM_ SG_ 1288 Position_setpoint "encoder ticks";
CM_ SG_ 1288 Speed_setpoint "encoder ticks/s";
CM_ SG_ 1288 Current_feedforward "mA";
CM_ SG_ 1342 Speed "encoder ticks/s; the sign gives the direction";
CM_ SG_ 1342 Trigger "0 = trigger when the pin is low, 1 = when it is high, 2 = on any edge";
CM_ SG_ 1286 position "encoder ticks";
CM_ SG_ 1286 speed "encoder ticks/s";
CM_ SG_ 1286 current "Iq in mA";
CM_ SG_ 1287 position "encoder ticks";
CM_ SG_ 1287 speed "encoder ticks/s";
CM_ SG_ 1287 current "Iq in mA";
CM_ SG_ 1344 position "encoder ticks";
CM_ SG_ 1344 HALL_trigger "1 while the driver waits for the trigger (with a level trigger, also again after the pin left the level), 0 while it holds";
CM_ SG_ 1344 additional_pin2 "the raw level of the ADDITIONAL2 pin";
CM_ SG_ 1344 hall_index "1 once the trigger has been seen (latched)";
CM_ SG_ 1345 position "encoder ticks";
CM_ SG_ 1345 HALL_trigger "1 while the driver waits for the trigger (with a level trigger, also again after the pin left the level), 0 while it holds";
CM_ SG_ 1345 additional_pin2 "the raw level of the ADDITIONAL2 pin";
CM_ SG_ 1345 hall_index "1 once the trigger has been seen (latched)";
CM_ SG_ 1320 Speed_limit "encoder ticks/s";
CM_ SG_ 1320 Current_limit "mA";
CM_ SG_ 1324 Kt "Nm/A";
CM_ SG_ 1348 Voltage_limit "mV; 0 = Vbus";
CM_ SG_ 1326 temperature "\u00b0C";
CM_ SG_ 1327 temperature "\u00b0C";
CM_ SG_ 1328 voltage "mV";
CM_ SG_ 1329 voltage "mV";
CM_ SG_ 1330 HARDWARE_VERSION "PCB revision";
CM_ SG_ 1330 BATCH_DATE "production batch";
CM_ SG_ 1330 SOFTWARE_VERSION "firmware release, e.g. 108";
CM_ SG_ 1330 SERIAL_NUMBER "serial number as held in RAM: 1 after a power-up";
CM_ SG_ 1331 HARDWARE_VERSION "PCB revision";
CM_ SG_ 1331 BATCH_DATE "production batch";
CM_ SG_ 1331 SOFTWARE_VERSION "firmware release, e.g. 108";
CM_ SG_ 1331 SERIAL_NUMBER "serial number as held in RAM: 1 after a power-up";
CM_ SG_ 1332 error "any error is active";
CM_ SG_ 1332 temperature_error "motor over the temperature limit";
CM_ SG_ 1332 encoder_error "the encoder reports no magnet (too weak a field)";
CM_ SG_ 1332 vbus_error "supply voltage outside the limits";
CM_ SG_ 1332 driver_error "reserved; never set by this firmware (STEPFOC does not read a fault output of its driver stage)";
CM_ SG_ 1332 velocity_error "speed above 30,000,000 ticks/s, a fixed threshold (not #Vlimit)";
CM_ SG_ 1332 current_error "reserved; never set by this firmware";
CM_ SG_ 1332 estop_error "Send_ESTOP was received";
CM_ SG_ 1332 calibrated "the motor is calibrated";
CM_ SG_ 1332 activated "the controller is activated";
CM_ SG_ 1332 watchdog_error "the watchdog ran out";
CM_ SG_ 1333 error "any error is active";
CM_ SG_ 1333 temperature_error "motor over the temperature limit";
CM_ SG_ 1333 encoder_error "the encoder reports no magnet (too weak a field)";
CM_ SG_ 1333 vbus_error "supply voltage outside the limits";
CM_ SG_ 1333 driver_error "reserved; never set by this firmware (STEPFOC does not read a fault output of its driver stage)";
CM_ SG_ 1333 velocity_error "speed above 30,000,000 ticks/s, a fixed threshold (not #Vlimit)";
CM_ SG_ 1333 current_error "reserved; never set by this firmware";
CM_ SG_ 1333 estop_error "Send_ESTOP was received";
CM_ SG_ 1333 calibrated "the motor is calibrated";
CM_ SG_ 1333 activated "the controller is activated";
CM_ SG_ 1333 watchdog_error "the watchdog ran out";
CM_ SG_ 1334 current "mA";
CM_ SG_ 1335 current "mA";
CM_ SG_ 1336 position "encoder ticks";
CM_ SG_ 1336 speed "encoder ticks/s";
CM_ SG_ 1337 position "encoder ticks";
CM_ SG_ 1337 speed "encoder ticks/s";
CM_ SG_ 1346 Kt "Nm/A";
CM_ SG_ 1347 Kt "Nm/A";
CM_ SG_ 1302 ID "0 to 13; 14 and 15 are accepted but reserved by the bootloader";
CM_ SG_ 1310 Time "ms; 0 = off";
CM_ SG_ 1310 Action "0 idle, 1 hold, 2 brake (stored only)";
CM_ SG_ 1340 Interval "ms; 0 = off";
CM_ SG_ 1350 Mask "bit 0 = write the idle behaviour";
CM_ SG_ 1350 Value "bit 0: 1 brake, 0 coast";
CM_ SG_ 1402 Position "0 fully open, 255 fully closed";
CM_ SG_ 1402 Speed "0 slowest, 255 fastest";
CM_ SG_ 1402 Current "current limit of the move in mA; not clamped by the firmware, not even to the driver's 2800 mA; see the gripper manual for the safe range";
CM_ SG_ 1402 Activate "1 activate the gripper, 0 deactivate";
CM_ SG_ 1402 Action "1 go to the position, 0 idle";
CM_ SG_ 1402 E_stop "1 raises the gripper E-stop error, again on every control cycle until a frame with this bit 0 arrives; then Send_Clear_Error";
CM_ SG_ 1402 Release_direction "read by the firmware but not used";
CM_ SG_ 1400 gripper_position "0 fully open, 255 fully closed";
CM_ SG_ 1400 gripper_current "measured current in mA";
CM_ SG_ 1400 gripper_activated "1 activated";
CM_ SG_ 1400 gripper_action_status "the action bit of the last Send_gripper_data_pack (1 after #Grippos); the driver never clears it, so it stays 1 after the move ends: the object detection tells when the move has ended";
CM_ SG_ 1400 gripper_object_detection_raw "bit 5 is the low bit, bit 4 the high bit: 0 moving, 1 object detected while closing, 2 object detected while opening, 3 at the position; raw bit pair, see value labels (wire order differs from numeric status)";
CM_ SG_ 1400 gripper_temperature_error "a copy of the thermistor temperature error";
CM_ SG_ 1400 gripper_timeout_error "a copy of the CAN watchdog error (Send_Watchdog), not a move timeout";
CM_ SG_ 1400 gripper_estop_error "the E-stop bit of Send_gripper_data_pack (or #Gripstop 1) was set";
CM_ SG_ 1400 gripper_calibrated "1 calibrated";
CM_ SG_ 1401 gripper_position "0 fully open, 255 fully closed";
CM_ SG_ 1401 gripper_current "measured current in mA";
CM_ SG_ 1401 gripper_activated "1 activated";
CM_ SG_ 1401 gripper_action_status "the action bit of the last Send_gripper_data_pack (1 after #Grippos); the driver never clears it, so it stays 1 after the move ends: the object detection tells when the move has ended";
CM_ SG_ 1401 gripper_object_detection_raw "bit 5 is the low bit, bit 4 the high bit: 0 moving, 1 object detected while closing, 2 object detected while opening, 3 at the position; raw bit pair, see value labels (wire order differs from numeric status)";
CM_ SG_ 1401 gripper_temperature_error "a copy of the thermistor temperature error";
CM_ SG_ 1401 gripper_timeout_error "a copy of the CAN watchdog error (Send_Watchdog), not a move timeout";
CM_ SG_ 1401 gripper_estop_error "the E-stop bit of Send_gripper_data_pack (or #Gripstop 1) was set";
CM_ SG_ 1401 gripper_calibrated "1 calibrated";
CM_ SG_ 1412 Speed_setpoint "encoder ticks/s";
CM_ SG_ 1412 Current_feedforward "mA";
CM_ SG_ 1416 Position_setpoint "encoder ticks";
CM_ SG_ 1416 Speed_setpoint "encoder ticks/s";
CM_ SG_ 1416 Current_feedforward "mA";
CM_ SG_ 1470 Speed "encoder ticks/s; the sign gives the direction";
CM_ SG_ 1470 Trigger "0 = trigger when the pin is low, 1 = when it is high, 2 = on any edge";
CM_ SG_ 1414 position "encoder ticks";
CM_ SG_ 1414 speed "encoder ticks/s";
CM_ SG_ 1414 current "Iq in mA";
CM_ SG_ 1415 position "encoder ticks";
CM_ SG_ 1415 speed "encoder ticks/s";
CM_ SG_ 1415 current "Iq in mA";
CM_ SG_ 1472 position "encoder ticks";
CM_ SG_ 1472 HALL_trigger "1 while the driver waits for the trigger (with a level trigger, also again after the pin left the level), 0 while it holds";
CM_ SG_ 1472 additional_pin2 "the raw level of the ADDITIONAL2 pin";
CM_ SG_ 1472 hall_index "1 once the trigger has been seen (latched)";
CM_ SG_ 1473 position "encoder ticks";
CM_ SG_ 1473 HALL_trigger "1 while the driver waits for the trigger (with a level trigger, also again after the pin left the level), 0 while it holds";
CM_ SG_ 1473 additional_pin2 "the raw level of the ADDITIONAL2 pin";
CM_ SG_ 1473 hall_index "1 once the trigger has been seen (latched)";
CM_ SG_ 1448 Speed_limit "encoder ticks/s";
CM_ SG_ 1448 Current_limit "mA";
CM_ SG_ 1452 Kt "Nm/A";
CM_ SG_ 1476 Voltage_limit "mV; 0 = Vbus";
CM_ SG_ 1454 temperature "\u00b0C";
CM_ SG_ 1455 temperature "\u00b0C";
CM_ SG_ 1456 voltage "mV";
CM_ SG_ 1457 voltage "mV";
CM_ SG_ 1458 HARDWARE_VERSION "PCB revision";
CM_ SG_ 1458 BATCH_DATE "production batch";
CM_ SG_ 1458 SOFTWARE_VERSION "firmware release, e.g. 108";
CM_ SG_ 1458 SERIAL_NUMBER "serial number as held in RAM: 1 after a power-up";
CM_ SG_ 1459 HARDWARE_VERSION "PCB revision";
CM_ SG_ 1459 BATCH_DATE "production batch";
CM_ SG_ 1459 SOFTWARE_VERSION "firmware release, e.g. 108";
CM_ SG_ 1459 SERIAL_NUMBER "serial number as held in RAM: 1 after a power-up";
CM_ SG_ 1460 error "any error is active";
CM_ SG_ 1460 temperature_error "motor over the temperature limit";
CM_ SG_ 1460 encoder_error "the encoder reports no magnet (too weak a field)";
CM_ SG_ 1460 vbus_error "supply voltage outside the limits";
CM_ SG_ 1460 driver_error "reserved; never set by this firmware (STEPFOC does not read a fault output of its driver stage)";
CM_ SG_ 1460 velocity_error "speed above 30,000,000 ticks/s, a fixed threshold (not #Vlimit)";
CM_ SG_ 1460 current_error "reserved; never set by this firmware";
CM_ SG_ 1460 estop_error "Send_ESTOP was received";
CM_ SG_ 1460 calibrated "the motor is calibrated";
CM_ SG_ 1460 activated "the controller is activated";
CM_ SG_ 1460 watchdog_error "the watchdog ran out";
CM_ SG_ 1461 error "any error is active";
CM_ SG_ 1461 temperature_error "motor over the temperature limit";
CM_ SG_ 1461 encoder_error "the encoder reports no magnet (too weak a field)";
CM_ SG_ 1461 vbus_error "supply voltage outside the limits";
CM_ SG_ 1461 driver_error "reserved; never set by this firmware (STEPFOC does not read a fault output of its driver stage)";
CM_ SG_ 1461 velocity_error "speed above 30,000,000 ticks/s, a fixed threshold (not #Vlimit)";
CM_ SG_ 1461 current_error "reserved; never set by this firmware";
CM_ SG_ 1461 estop_error "Send_ESTOP was received";
CM_ SG_ 1461 calibrated "the motor is calibrated";
CM_ SG_ 1461 activated "the controller is activated";
CM_ SG_ 1461 watchdog_error "the watchdog ran out";
CM_ SG_ 1462 current "mA";
CM_ SG_ 1463 current "mA";
CM_ SG_ 1464 position "encoder ticks";
CM_ SG_ 1464 speed "encoder ticks/s";
CM_ SG_ 1465 position "encoder ticks";
CM_ SG_ 1465 speed "encoder ticks/s";
CM_ SG_ 1474 Kt "Nm/A";
CM_ SG_ 1475 Kt "Nm/A";
CM_ SG_ 1430 ID "0 to 13; 14 and 15 are accepted but reserved by the bootloader";
CM_ SG_ 1438 Time "ms; 0 = off";
CM_ SG_ 1438 Action "0 idle, 1 hold, 2 brake (stored only)";
CM_ SG_ 1468 Interval "ms; 0 = off";
CM_ SG_ 1478 Mask "bit 0 = write the idle behaviour";
CM_ SG_ 1478 Value "bit 0: 1 brake, 0 coast";
CM_ SG_ 1530 Position "0 fully open, 255 fully closed";
CM_ SG_ 1530 Speed "0 slowest, 255 fastest";
CM_ SG_ 1530 Current "current limit of the move in mA; not clamped by the firmware, not even to the driver's 2800 mA; see the gripper manual for the safe range";
CM_ SG_ 1530 Activate "1 activate the gripper, 0 deactivate";
CM_ SG_ 1530 Action "1 go to the position, 0 idle";
CM_ SG_ 1530 E_stop "1 raises the gripper E-stop error, again on every control cycle until a frame with this bit 0 arrives; then Send_Clear_Error";
CM_ SG_ 1530 Release_direction "read by the firmware but not used";
CM_ SG_ 1528 gripper_position "0 fully open, 255 fully closed";
CM_ SG_ 1528 gripper_current "measured current in mA";
CM_ SG_ 1528 gripper_activated "1 activated";
CM_ SG_ 1528 gripper_action_status "the action bit of the last Send_gripper_data_pack (1 after #Grippos); the driver never clears it, so it stays 1 after the move ends: the object detection tells when the move has ended";
CM_ SG_ 1528 gripper_object_detection_raw "bit 5 is the low bit, bit 4 the high bit: 0 moving, 1 object detected while closing, 2 object detected while opening, 3 at the position; raw bit pair, see value labels (wire order differs from numeric status)";
CM_ SG_ 1528 gripper_temperature_error "a copy of the thermistor temperature error";
CM_ SG_ 1528 gripper_timeout_error "a copy of the CAN watchdog error (Send_Watchdog), not a move timeout";
CM_ SG_ 1528 gripper_estop_error "the E-stop bit of Send_gripper_data_pack (or #Gripstop 1) was set";
CM_ SG_ 1528 gripper_calibrated "1 calibrated";
CM_ SG_ 1529 gripper_position "0 fully open, 255 fully closed";
CM_ SG_ 1529 gripper_current "measured current in mA";
CM_ SG_ 1529 gripper_activated "1 activated";
CM_ SG_ 1529 gripper_action_status "the action bit of the last Send_gripper_data_pack (1 after #Grippos); the driver never clears it, so it stays 1 after the move ends: the object detection tells when the move has ended";
CM_ SG_ 1529 gripper_object_detection_raw "bit 5 is the low bit, bit 4 the high bit: 0 moving, 1 object detected while closing, 2 object detected while opening, 3 at the position; raw bit pair, see value labels (wire order differs from numeric status)";
CM_ SG_ 1529 gripper_temperature_error "a copy of the thermistor temperature error";
CM_ SG_ 1529 gripper_timeout_error "a copy of the CAN watchdog error (Send_Watchdog), not a move timeout";
CM_ SG_ 1529 gripper_estop_error "the E-stop bit of Send_gripper_data_pack (or #Gripstop 1) was set";
CM_ SG_ 1529 gripper_calibrated "1 calibrated";
CM_ SG_ 1540 Speed_setpoint "encoder ticks/s";
CM_ SG_ 1540 Current_feedforward "mA";
CM_ SG_ 1544 Position_setpoint "encoder ticks";
CM_ SG_ 1544 Speed_setpoint "encoder ticks/s";
CM_ SG_ 1544 Current_feedforward "mA";
CM_ SG_ 1598 Speed "encoder ticks/s; the sign gives the direction";
CM_ SG_ 1598 Trigger "0 = trigger when the pin is low, 1 = when it is high, 2 = on any edge";
CM_ SG_ 1542 position "encoder ticks";
CM_ SG_ 1542 speed "encoder ticks/s";
CM_ SG_ 1542 current "Iq in mA";
CM_ SG_ 1543 position "encoder ticks";
CM_ SG_ 1543 speed "encoder ticks/s";
CM_ SG_ 1543 current "Iq in mA";
CM_ SG_ 1600 position "encoder ticks";
CM_ SG_ 1600 HALL_trigger "1 while the driver waits for the trigger (with a level trigger, also again after the pin left the level), 0 while it holds";
CM_ SG_ 1600 additional_pin2 "the raw level of the ADDITIONAL2 pin";
CM_ SG_ 1600 hall_index "1 once the trigger has been seen (latched)";
CM_ SG_ 1601 position "encoder ticks";
CM_ SG_ 1601 HALL_trigger "1 while the driver waits for the trigger (with a level trigger, also again after the pin left the level), 0 while it holds";
CM_ SG_ 1601 additional_pin2 "the raw level of the ADDITIONAL2 pin";
CM_ SG_ 1601 hall_index "1 once the trigger has been seen (latched)";
CM_ SG_ 1576 Speed_limit "encoder ticks/s";
CM_ SG_ 1576 Current_limit "mA";
CM_ SG_ 1580 Kt "Nm/A";
CM_ SG_ 1604 Voltage_limit "mV; 0 = Vbus";
CM_ SG_ 1582 temperature "\u00b0C";
CM_ SG_ 1583 temperature "\u00b0C";
CM_ SG_ 1584 voltage "mV";
CM_ SG_ 1585 voltage "mV";
CM_ SG_ 1586 HARDWARE_VERSION "PCB revision";
CM_ SG_ 1586 BATCH_DATE "production batch";
CM_ SG_ 1586 SOFTWARE_VERSION "firmware release, e.g. 108";
CM_ SG_ 1586 SERIAL_NUMBER "serial number as held in RAM: 1 after a power-up";
CM_ SG_ 1587 HARDWARE_VERSION "PCB revision";
CM_ SG_ 1587 BATCH_DATE "production batch";
CM_ SG_ 1587 SOFTWARE_VERSION "firmware release, e.g. 108";
CM_ SG_ 1587 SERIAL_NUMBER "serial number as held in RAM: 1 after a power-up";
CM_ SG_ 1588 error "any error is active";
CM_ SG_ 1588 temperature_error "motor over the temperature limit";
CM_ SG_ 1588 encoder_error "the encoder reports no magnet (too weak a field)";
CM_ SG_ 1588 vbus_error "supply voltage outside the limits";
CM_ SG_ 1588 driver_error "reserved; never set by this firmware (STEPFOC does not read a fault output of its driver stage)";
CM_ SG_ 1588 velocity_error "speed above 30,000,000 ticks/s, a fixed threshold (not #Vlimit)";
CM_ SG_ 1588 current_error "reserved; never set by this firmware";
CM_ SG_ 1588 estop_error "Send_ESTOP was received";
CM_ SG_ 1588 calibrated "the motor is calibrated";
CM_ SG_ 1588 activated "the controller is activated";
CM_ SG_ 1588 watchdog_error "the watchdog ran out";
CM_ SG_ 1589 error "any error is active";
CM_ SG_ 1589 temperature_error "motor over the temperature limit";
CM_ SG_ 1589 encoder_error "the encoder reports no magnet (too weak a field)";
CM_ SG_ 1589 vbus_error "supply voltage outside the limits";
CM_ SG_ 1589 driver_error "reserved; never set by this firmware (STEPFOC does not read a fault output of its driver stage)";
CM_ SG_ 1589 velocity_error "speed above 30,000,000 ticks/s, a fixed threshold (not #Vlimit)";
CM_ SG_ 1589 current_error "reserved; never set by this firmware";
CM_ SG_ 1589 estop_error "Send_ESTOP was received";
CM_ SG_ 1589 calibrated "the motor is calibrated";
CM_ SG_ 1589 activated "the controller is activated";
CM_ SG_ 1589 watchdog_error "the watchdog ran out";
CM_ SG_ 1590 current "mA";
CM_ SG_ 1591 current "mA";
CM_ SG_ 1592 position "encoder ticks";
CM_ SG_ 1592 speed "encoder ticks/s";
CM_ SG_ 1593 position "encoder ticks";
CM_ SG_ 1593 speed "encoder ticks/s";
CM_ SG_ 1602 Kt "Nm/A";
CM_ SG_ 1603 Kt "Nm/A";
CM_ SG_ 1558 ID "0 to 13; 14 and 15 are accepted but reserved by the bootloader";
CM_ SG_ 1566 Time "ms; 0 = off";
CM_ SG_ 1566 Action "0 idle, 1 hold, 2 brake (stored only)";
CM_ SG_ 1596 Interval "ms; 0 = off";
CM_ SG_ 1606 Mask "bit 0 = write the idle behaviour";
CM_ SG_ 1606 Value "bit 0: 1 brake, 0 coast";
CM_ SG_ 1658 Position "0 fully open, 255 fully closed";
CM_ SG_ 1658 Speed "0 slowest, 255 fastest";
CM_ SG_ 1658 Current "current limit of the move in mA; not clamped by the firmware, not even to the driver's 2800 mA; see the gripper manual for the safe range";
CM_ SG_ 1658 Activate "1 activate the gripper, 0 deactivate";
CM_ SG_ 1658 Action "1 go to the position, 0 idle";
CM_ SG_ 1658 E_stop "1 raises the gripper E-stop error, again on every control cycle until a frame with this bit 0 arrives; then Send_Clear_Error";
CM_ SG_ 1658 Release_direction "read by the firmware but not used";
CM_ SG_ 1656 gripper_position "0 fully open, 255 fully closed";
CM_ SG_ 1656 gripper_current "measured current in mA";
CM_ SG_ 1656 gripper_activated "1 activated";
CM_ SG_ 1656 gripper_action_status "the action bit of the last Send_gripper_data_pack (1 after #Grippos); the driver never clears it, so it stays 1 after the move ends: the object detection tells when the move has ended";
CM_ SG_ 1656 gripper_object_detection_raw "bit 5 is the low bit, bit 4 the high bit: 0 moving, 1 object detected while closing, 2 object detected while opening, 3 at the position; raw bit pair, see value labels (wire order differs from numeric status)";
CM_ SG_ 1656 gripper_temperature_error "a copy of the thermistor temperature error";
CM_ SG_ 1656 gripper_timeout_error "a copy of the CAN watchdog error (Send_Watchdog), not a move timeout";
CM_ SG_ 1656 gripper_estop_error "the E-stop bit of Send_gripper_data_pack (or #Gripstop 1) was set";
CM_ SG_ 1656 gripper_calibrated "1 calibrated";
CM_ SG_ 1657 gripper_position "0 fully open, 255 fully closed";
CM_ SG_ 1657 gripper_current "measured current in mA";
CM_ SG_ 1657 gripper_activated "1 activated";
CM_ SG_ 1657 gripper_action_status "the action bit of the last Send_gripper_data_pack (1 after #Grippos); the driver never clears it, so it stays 1 after the move ends: the object detection tells when the move has ended";
CM_ SG_ 1657 gripper_object_detection_raw "bit 5 is the low bit, bit 4 the high bit: 0 moving, 1 object detected while closing, 2 object detected while opening, 3 at the position; raw bit pair, see value labels (wire order differs from numeric status)";
CM_ SG_ 1657 gripper_temperature_error "a copy of the thermistor temperature error";
CM_ SG_ 1657 gripper_timeout_error "a copy of the CAN watchdog error (Send_Watchdog), not a move timeout";
CM_ SG_ 1657 gripper_estop_error "the E-stop bit of Send_gripper_data_pack (or #Gripstop 1) was set";
CM_ SG_ 1657 gripper_calibrated "1 calibrated";
CM_ SG_ 1668 Speed_setpoint "encoder ticks/s";
CM_ SG_ 1668 Current_feedforward "mA";
CM_ SG_ 1672 Position_setpoint "encoder ticks";
CM_ SG_ 1672 Speed_setpoint "encoder ticks/s";
CM_ SG_ 1672 Current_feedforward "mA";
CM_ SG_ 1726 Speed "encoder ticks/s; the sign gives the direction";
CM_ SG_ 1726 Trigger "0 = trigger when the pin is low, 1 = when it is high, 2 = on any edge";
CM_ SG_ 1670 position "encoder ticks";
CM_ SG_ 1670 speed "encoder ticks/s";
CM_ SG_ 1670 current "Iq in mA";
CM_ SG_ 1671 position "encoder ticks";
CM_ SG_ 1671 speed "encoder ticks/s";
CM_ SG_ 1671 current "Iq in mA";
CM_ SG_ 1728 position "encoder ticks";
CM_ SG_ 1728 HALL_trigger "1 while the driver waits for the trigger (with a level trigger, also again after the pin left the level), 0 while it holds";
CM_ SG_ 1728 additional_pin2 "the raw level of the ADDITIONAL2 pin";
CM_ SG_ 1728 hall_index "1 once the trigger has been seen (latched)";
CM_ SG_ 1729 position "encoder ticks";
CM_ SG_ 1729 HALL_trigger "1 while the driver waits for the trigger (with a level trigger, also again after the pin left the level), 0 while it holds";
CM_ SG_ 1729 additional_pin2 "the raw level of the ADDITIONAL2 pin";
CM_ SG_ 1729 hall_index "1 once the trigger has been seen (latched)";
CM_ SG_ 1704 Speed_limit "encoder ticks/s";
CM_ SG_ 1704 Current_limit "mA";
CM_ SG_ 1708 Kt "Nm/A";
CM_ SG_ 1732 Voltage_limit "mV; 0 = Vbus";
CM_ SG_ 1710 temperature "\u00b0C";
CM_ SG_ 1711 temperature "\u00b0C";
CM_ SG_ 1712 voltage "mV";
CM_ SG_ 1713 voltage "mV";
CM_ SG_ 1714 HARDWARE_VERSION "PCB revision";
CM_ SG_ 1714 BATCH_DATE "production batch";
CM_ SG_ 1714 SOFTWARE_VERSION "firmware release, e.g. 108";
CM_ SG_ 1714 SERIAL_NUMBER "serial number as held in RAM: 1 after a power-up";
CM_ SG_ 1715 HARDWARE_VERSION "PCB revision";
CM_ SG_ 1715 BATCH_DATE "production batch";
CM_ SG_ 1715 SOFTWARE_VERSION "firmware release, e.g. 108";
CM_ SG_ 1715 SERIAL_NUMBER "serial number as held in RAM: 1 after a power-up";
CM_ SG_ 1716 error "any error is active";
CM_ SG_ 1716 temperature_error "motor over the temperature limit";
CM_ SG_ 1716 encoder_error "the encoder reports no magnet (too weak a field)";
CM_ SG_ 1716 vbus_error "supply voltage outside the limits";
CM_ SG_ 1716 driver_error "reserved; never set by this firmware (STEPFOC does not read a fault output of its driver stage)";
CM_ SG_ 1716 velocity_error "speed above 30,000,000 ticks/s, a fixed threshold (not #Vlimit)";
CM_ SG_ 1716 current_error "reserved; never set by this firmware";
CM_ SG_ 1716 estop_error "Send_ESTOP was received";
CM_ SG_ 1716 calibrated "the motor is calibrated";
CM_ SG_ 1716 activated "the controller is activated";
CM_ SG_ 1716 watchdog_error "the watchdog ran out";
CM_ SG_ 1717 error "any error is active";
CM_ SG_ 1717 temperature_error "motor over the temperature limit";
CM_ SG_ 1717 encoder_error "the encoder reports no magnet (too weak a field)";
CM_ SG_ 1717 vbus_error "supply voltage outside the limits";
CM_ SG_ 1717 driver_error "reserved; never set by this firmware (STEPFOC does not read a fault output of its driver stage)";
CM_ SG_ 1717 velocity_error "speed above 30,000,000 ticks/s, a fixed threshold (not #Vlimit)";
CM_ SG_ 1717 current_error "reserved; never set by this firmware";
CM_ SG_ 1717 estop_error "Send_ESTOP was received";
CM_ SG_ 1717 calibrated "the motor is calibrated";
CM_ SG_ 1717 activated "the controller is activated";
CM_ SG_ 1717 watchdog_error "the watchdog ran out";
CM_ SG_ 1718 current "mA";
CM_ SG_ 1719 current "mA";
CM_ SG_ 1720 position "encoder ticks";
CM_ SG_ 1720 speed "encoder ticks/s";
CM_ SG_ 1721 position "encoder ticks";
CM_ SG_ 1721 speed "encoder ticks/s";
CM_ SG_ 1730 Kt "Nm/A";
CM_ SG_ 1731 Kt "Nm/A";
CM_ SG_ 1686 ID "0 to 13; 14 and 15 are accepted but reserved by the bootloader";
CM_ SG_ 1694 Time "ms; 0 = off";
CM_ SG_ 1694 Action "0 idle, 1 hold, 2 brake (stored only)";
CM_ SG_ 1724 Interval "ms; 0 = off";
CM_ SG_ 1734 Mask "bit 0 = write the idle behaviour";
CM_ SG_ 1734 Value "bit 0: 1 brake, 0 coast";
CM_ SG_ 1786 Position "0 fully open, 255 fully closed";
CM_ SG_ 1786 Speed "0 slowest, 255 fastest";
CM_ SG_ 1786 Current "current limit of the move in mA; not clamped by the firmware, not even to the driver's 2800 mA; see the gripper manual for the safe range";
CM_ SG_ 1786 Activate "1 activate the gripper, 0 deactivate";
CM_ SG_ 1786 Action "1 go to the position, 0 idle";
CM_ SG_ 1786 E_stop "1 raises the gripper E-stop error, again on every control cycle until a frame with this bit 0 arrives; then Send_Clear_Error";
CM_ SG_ 1786 Release_direction "read by the firmware but not used";
CM_ SG_ 1784 gripper_position "0 fully open, 255 fully closed";
CM_ SG_ 1784 gripper_current "measured current in mA";
CM_ SG_ 1784 gripper_activated "1 activated";
CM_ SG_ 1784 gripper_action_status "the action bit of the last Send_gripper_data_pack (1 after #Grippos); the driver never clears it, so it stays 1 after the move ends: the object detection tells when the move has ended";
CM_ SG_ 1784 gripper_object_detection_raw "bit 5 is the low bit, bit 4 the high bit: 0 moving, 1 object detected while closing, 2 object detected while opening, 3 at the position; raw bit pair, see value labels (wire order differs from numeric status)";
CM_ SG_ 1784 gripper_temperature_error "a copy of the thermistor temperature error";
CM_ SG_ 1784 gripper_timeout_error "a copy of the CAN watchdog error (Send_Watchdog), not a move timeout";
CM_ SG_ 1784 gripper_estop_error "the E-stop bit of Send_gripper_data_pack (or #Gripstop 1) was set";
CM_ SG_ 1784 gripper_calibrated "1 calibrated";
CM_ SG_ 1785 gripper_position "0 fully open, 255 fully closed";
CM_ SG_ 1785 gripper_current "measured current in mA";
CM_ SG_ 1785 gripper_activated "1 activated";
CM_ SG_ 1785 gripper_action_status "the action bit of the last Send_gripper_data_pack (1 after #Grippos); the driver never clears it, so it stays 1 after the move ends: the object detection tells when the move has ended";
CM_ SG_ 1785 gripper_object_detection_raw "bit 5 is the low bit, bit 4 the high bit: 0 moving, 1 object detected while closing, 2 object detected while opening, 3 at the position; raw bit pair, see value labels (wire order differs from numeric status)";
CM_ SG_ 1785 gripper_temperature_error "a copy of the thermistor temperature error";
CM_ SG_ 1785 gripper_timeout_error "a copy of the CAN watchdog error (Send_Watchdog), not a move timeout";
CM_ SG_ 1785 gripper_estop_error "the E-stop bit of Send_gripper_data_pack (or #Gripstop 1) was set";
CM_ SG_ 1785 gripper_calibrated "1 calibrated";
SIG_VALTYPE_ 928 KP : 1;
SIG_VALTYPE_ 928 KD : 1;
SIG_VALTYPE_ 930 Kp_iq : 1;
SIG_VALTYPE_ 930 Ki_iq : 1;
SIG_VALTYPE_ 932 Kpv : 1;
SIG_VALTYPE_ 932 Kiv : 1;
SIG_VALTYPE_ 934 Kpp : 1;
SIG_VALTYPE_ 936 Speed_limit : 1;
SIG_VALTYPE_ 936 Current_limit : 1;
SIG_VALTYPE_ 940 Kt : 1;
SIG_VALTYPE_ 962 Kt : 1;
SIG_VALTYPE_ 963 Kt : 1;
SIG_VALTYPE_ 1056 KP : 1;
SIG_VALTYPE_ 1056 KD : 1;
SIG_VALTYPE_ 1058 Kp_iq : 1;
SIG_VALTYPE_ 1058 Ki_iq : 1;
SIG_VALTYPE_ 1060 Kpv : 1;
SIG_VALTYPE_ 1060 Kiv : 1;
SIG_VALTYPE_ 1062 Kpp : 1;
SIG_VALTYPE_ 1064 Speed_limit : 1;
SIG_VALTYPE_ 1064 Current_limit : 1;
SIG_VALTYPE_ 1068 Kt : 1;
SIG_VALTYPE_ 1090 Kt : 1;
SIG_VALTYPE_ 1091 Kt : 1;
SIG_VALTYPE_ 1184 KP : 1;
SIG_VALTYPE_ 1184 KD : 1;
SIG_VALTYPE_ 1186 Kp_iq : 1;
SIG_VALTYPE_ 1186 Ki_iq : 1;
SIG_VALTYPE_ 1188 Kpv : 1;
SIG_VALTYPE_ 1188 Kiv : 1;
SIG_VALTYPE_ 1190 Kpp : 1;
SIG_VALTYPE_ 1192 Speed_limit : 1;
SIG_VALTYPE_ 1192 Current_limit : 1;
SIG_VALTYPE_ 1196 Kt : 1;
SIG_VALTYPE_ 1218 Kt : 1;
SIG_VALTYPE_ 1219 Kt : 1;
SIG_VALTYPE_ 1312 KP : 1;
SIG_VALTYPE_ 1312 KD : 1;
SIG_VALTYPE_ 1314 Kp_iq : 1;
SIG_VALTYPE_ 1314 Ki_iq : 1;
SIG_VALTYPE_ 1316 Kpv : 1;
SIG_VALTYPE_ 1316 Kiv : 1;
SIG_VALTYPE_ 1318 Kpp : 1;
SIG_VALTYPE_ 1320 Speed_limit : 1;
SIG_VALTYPE_ 1320 Current_limit : 1;
SIG_VALTYPE_ 1324 Kt : 1;
SIG_VALTYPE_ 1346 Kt : 1;
SIG_VALTYPE_ 1347 Kt : 1;
SIG_VALTYPE_ 1440 KP : 1;
SIG_VALTYPE_ 1440 KD : 1;
SIG_VALTYPE_ 1442 Kp_iq : 1;
SIG_VALTYPE_ 1442 Ki_iq : 1;
SIG_VALTYPE_ 1444 Kpv : 1;
SIG_VALTYPE_ 1444 Kiv : 1;
SIG_VALTYPE_ 1446 Kpp : 1;
SIG_VALTYPE_ 1448 Speed_limit : 1;
SIG_VALTYPE_ 1448 Current_limit : 1;
SIG_VALTYPE_ 1452 Kt : 1;
SIG_VALTYPE_ 1474 Kt : 1;
SIG_VALTYPE_ 1475 Kt : 1;
SIG_VALTYPE_ 1568 KP : 1;
SIG_VALTYPE_ 1568 KD : 1;
SIG_VALTYPE_ 1570 Kp_iq : 1;
SIG_VALTYPE_ 1570 Ki_iq : 1;
SIG_VALTYPE_ 1572 Kpv : 1;
SIG_VALTYPE_ 1572 Kiv : 1;
SIG_VALTYPE_ 1574 Kpp : 1;
SIG_VALTYPE_ 1576 Speed_limit : 1;
SIG_VALTYPE_ 1576 Current_limit : 1;
SIG_VALTYPE_ 1580 Kt : 1;
SIG_VALTYPE_ 1602 Kt : 1;
SIG_VALTYPE_ 1603 Kt : 1;
SIG_VALTYPE_ 1696 KP : 1;
SIG_VALTYPE_ 1696 KD : 1;
SIG_VALTYPE_ 1698 Kp_iq : 1;
SIG_VALTYPE_ 1698 Ki_iq : 1;
SIG_VALTYPE_ 1700 Kpv : 1;
SIG_VALTYPE_ 1700 Kiv : 1;
SIG_VALTYPE_ 1702 Kpp : 1;
SIG_VALTYPE_ 1704 Speed_limit : 1;
SIG_VALTYPE_ 1704 Current_limit : 1;
SIG_VALTYPE_ 1708 Kt : 1;
SIG_VALTYPE_ 1730 Kt : 1;
SIG_VALTYPE_ 1731 Kt : 1;
VAL_ 1016 gripper_object_detection_raw 0 "moving" 1 "object while opening" 2 "object while closing" 3 "at position";
VAL_ 1017 gripper_object_detection_raw 0 "moving" 1 "object while opening" 2 "object while closing" 3 "at position";
VAL_ 1144 gripper_object_detection_raw 0 "moving" 1 "object while opening" 2 "object while closing" 3 "at position";
VAL_ 1145 gripper_object_detection_raw 0 "moving" 1 "object while opening" 2 "object while closing" 3 "at position";
VAL_ 1272 gripper_object_detection_raw 0 "moving" 1 "object while opening" 2 "object while closing" 3 "at position";
VAL_ 1273 gripper_object_detection_raw 0 "moving" 1 "object while opening" 2 "object while closing" 3 "at position";
VAL_ 1400 gripper_object_detection_raw 0 "moving" 1 "object while opening" 2 "object while closing" 3 "at position";
VAL_ 1401 gripper_object_detection_raw 0 "moving" 1 "object while opening" 2 "object while closing" 3 "at position";
VAL_ 1528 gripper_object_detection_raw 0 "moving" 1 "object while opening" 2 "object while closing" 3 "at position";
VAL_ 1529 gripper_object_detection_raw 0 "moving" 1 "object while opening" 2 "object while closing" 3 "at position";
VAL_ 1656 gripper_object_detection_raw 0 "moving" 1 "object while opening" 2 "object while closing" 3 "at position";
VAL_ 1657 gripper_object_detection_raw 0 "moving" 1 "object while opening" 2 "object while closing" 3 "at position";
VAL_ 1784 gripper_object_detection_raw 0 "moving" 1 "object while opening" 2 "object while closing" 3 "at position";
VAL_ 1785 gripper_object_detection_raw 0 "moving" 1 "object while opening" 2 "object while closing" 3 "at position";
